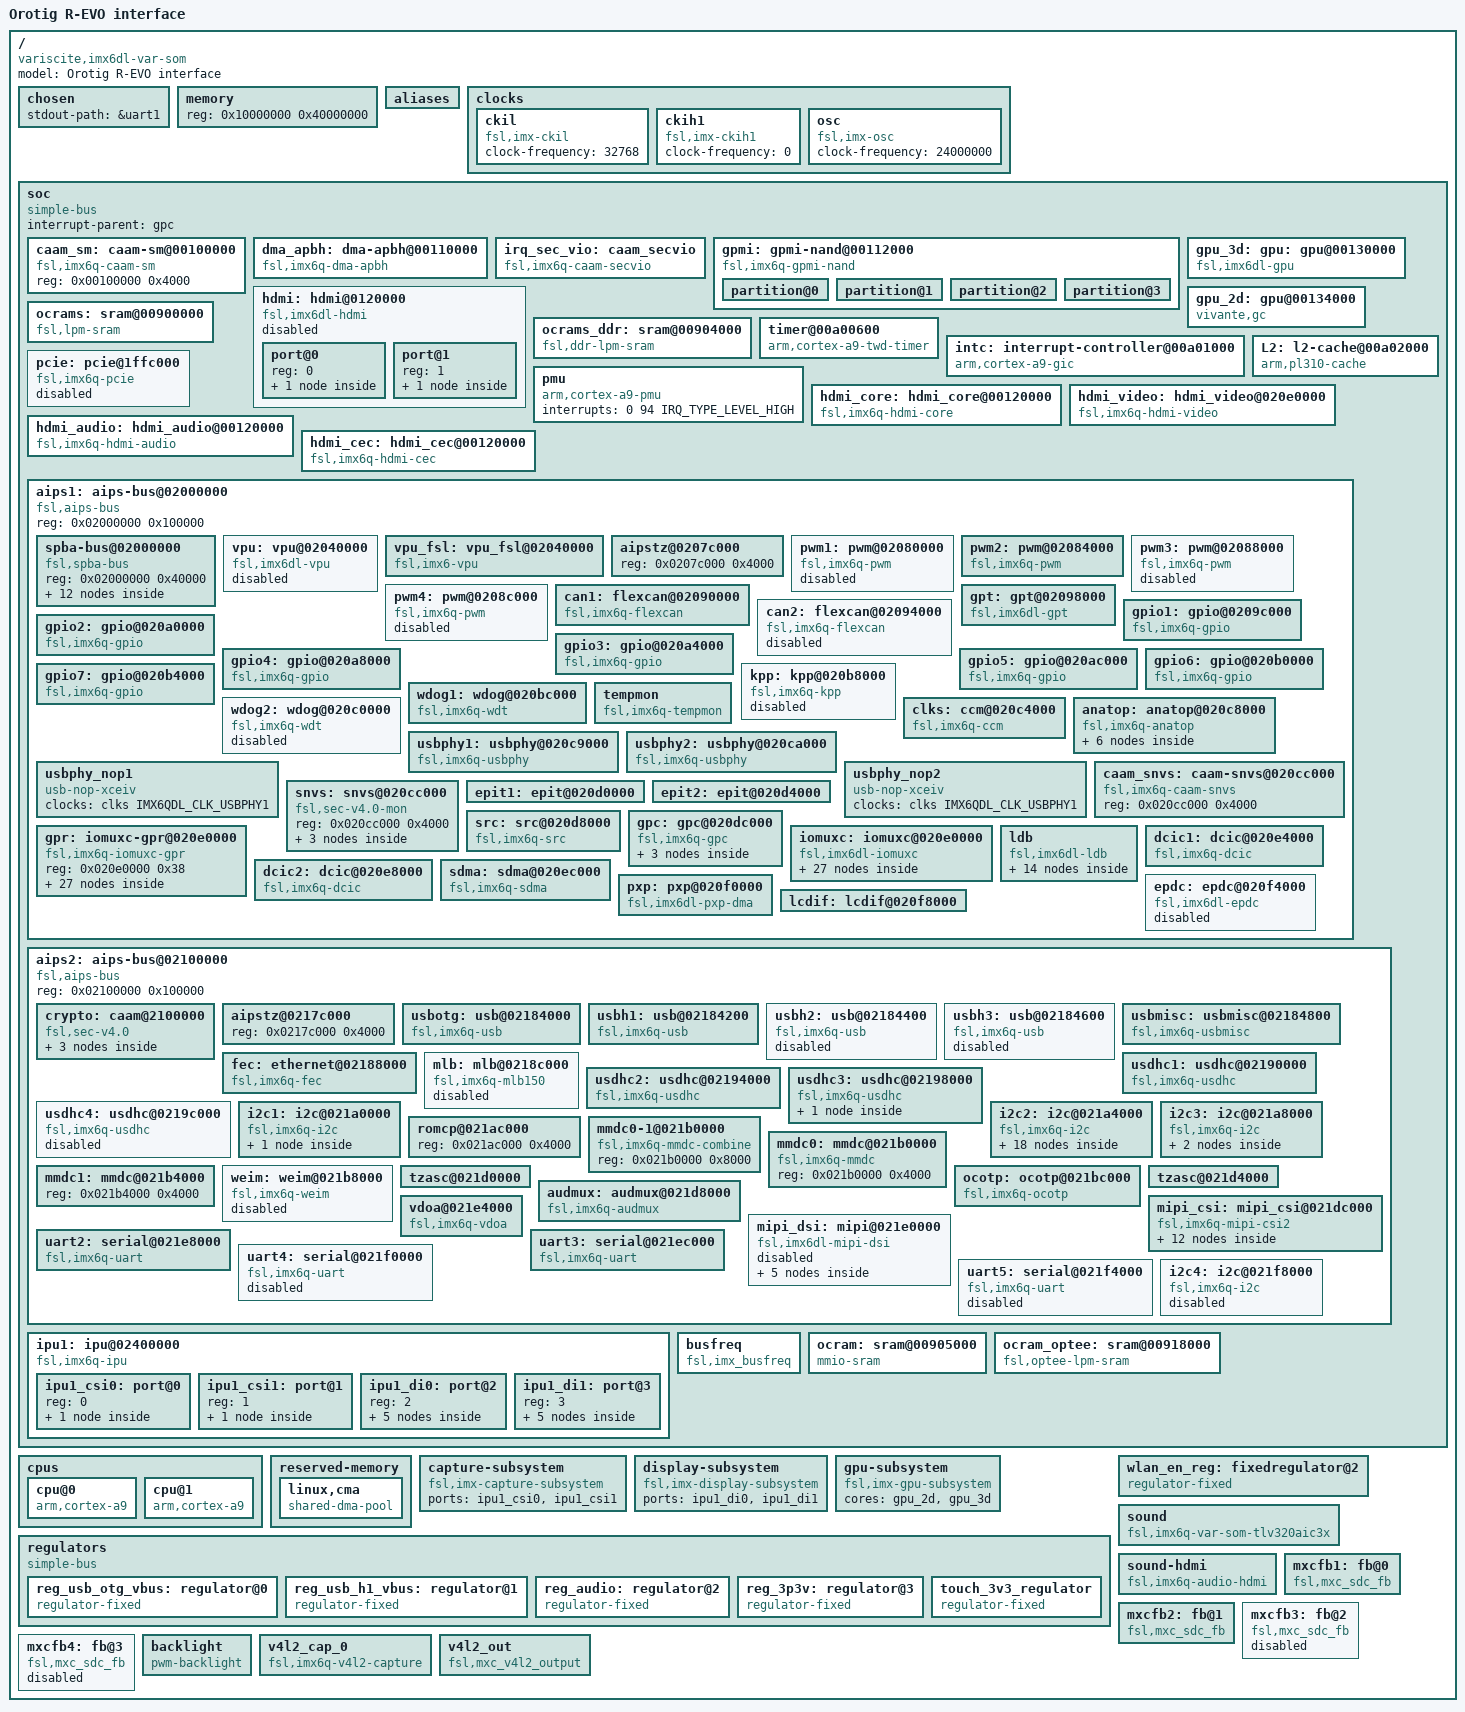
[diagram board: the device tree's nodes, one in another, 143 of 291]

/*
 * Copyright (C) 2015-2017 Variscite Ltd.
 *
 * This program is free software; you can redistribute it and/or modify
 * it under the terms of the GNU General Public License version 2 as
 * published by the Free Software Foundation.
 */

/dts-v1/;

#include <dt-bindings/interrupt-controller/irq.h>
#include "imx6dl-pinfunc.h"
#include <dt-bindings/clock/imx6qdl-clock.h>
#include <dt-bindings/input/input.h>
#include <dt-bindings/interrupt-controller/arm-gic.h>
#include <dt-bindings/gpio/gpio.h>

/ {
	model = "Orotig R-EVO interface";
	compatible = "variscite,imx6dl-var-som", "fsl,imx6dl";
};

/ {
	#address-cells = <1>;
	#size-cells = <1>;
	/*
	 * The decompressor and also some bootloaders rely on a
	 * pre-existing /chosen node to be available to insert the
	 * command line and merge other ATAGS info.
	 * Also for U-Boot there must be a pre-existing /memory node.
	 */
	chosen {};
	memory { device_type = "memory"; reg = <0 0>; };

	aliases {
		ethernet0 = &fec;
		can0 = &can1;
		can1 = &can2;
		gpio0 = &gpio1;
		gpio1 = &gpio2;
		gpio2 = &gpio3;
		gpio3 = &gpio4;
		gpio4 = &gpio5;
		gpio5 = &gpio6;
		gpio6 = &gpio7;
		i2c0 = &i2c1;
		i2c1 = &i2c2;
		i2c2 = &i2c3;
		ipu0 = &ipu1;
		mmc0 = &usdhc1;
		mmc1 = &usdhc2;
		mmc2 = &usdhc3;
		mmc3 = &usdhc4;
		serial0 = &uart1;
		serial1 = &uart2;
		serial2 = &uart3;
		serial3 = &uart4;
		serial4 = &uart5;
		spi0 = &ecspi1;
		spi1 = &ecspi2;
		spi2 = &ecspi3;
		spi3 = &ecspi4;
		usbphy0 = &usbphy1;
		usbphy1 = &usbphy2;
	};

	clocks {
		#address-cells = <1>;
		#size-cells = <0>;

		ckil {
			compatible = "fsl,imx-ckil", "fixed-clock";
			#clock-cells = <0>;
			clock-frequency = <32768>;
		};

		ckih1 {
			compatible = "fsl,imx-ckih1", "fixed-clock";
			#clock-cells = <0>;
			clock-frequency = <0>;
		};

		osc {
			compatible = "fsl,imx-osc", "fixed-clock";
			#clock-cells = <0>;
			clock-frequency = <24000000>;
		};
	};

	soc {
		#address-cells = <1>;
		#size-cells = <1>;
		compatible = "simple-bus";
		interrupt-parent = <&gpc>;
		ranges;

		caam_sm: caam-sm@00100000 {
			compatible = "fsl,imx6q-caam-sm";
			reg = <0x00100000 0x4000>;
		};

		dma_apbh: dma-apbh@00110000 {
			compatible = "fsl,imx6q-dma-apbh", "fsl,imx28-dma-apbh";
			reg = <0x00110000 0x2000>;
			interrupts = <0 13 IRQ_TYPE_LEVEL_HIGH>,
				     <0 13 IRQ_TYPE_LEVEL_HIGH>,
				     <0 13 IRQ_TYPE_LEVEL_HIGH>,
				     <0 13 IRQ_TYPE_LEVEL_HIGH>;
			interrupt-names = "gpmi0", "gpmi1", "gpmi2", "gpmi3";
			#dma-cells = <1>;
			dma-channels = <4>;
			clocks = <&clks IMX6QDL_CLK_APBH_DMA>;
		};

		irq_sec_vio: caam_secvio {
			compatible = "fsl,imx6q-caam-secvio";
			interrupts = <0 20 0x04>;
			secvio_src = <0x8000001d>;
			jtag-tamper = "disabled";
			watchdog-tamper = "enabled";
			internal-boot-tamper = "enabled";
			external-pin-tamper = "disabled";
		};

		gpmi: gpmi-nand@00112000 {
			compatible = "fsl,imx6q-gpmi-nand";
			#address-cells = <1>;
			#size-cells = <1>;
			reg = <0x00112000 0x2000>, <0x00114000 0x2000>;
			reg-names = "gpmi-nand", "bch";
			interrupts = <0 15 IRQ_TYPE_LEVEL_HIGH>;
			interrupt-names = "bch";
			clocks = <&clks IMX6QDL_CLK_GPMI_IO>,
				 <&clks IMX6QDL_CLK_GPMI_APB>,
				 <&clks IMX6QDL_CLK_GPMI_BCH>,
				 <&clks IMX6QDL_CLK_GPMI_BCH_APB>,
				 <&clks IMX6QDL_CLK_PER1_BCH>;
			clock-names = "gpmi_io", "gpmi_apb", "gpmi_bch",
				      "gpmi_bch_apb", "per1_bch";
			dmas = <&dma_apbh 0>;
			dma-names = "rx-tx";
			status = "disabled";
		};

		hdmi: hdmi@0120000 {
			#address-cells = <1>;
			#size-cells = <0>;
			reg = <0x00120000 0x9000>;
			interrupts = <0 115 0x04>;
			gpr = <&gpr>;
			clocks = <&clks IMX6QDL_CLK_HDMI_IAHB>,
				 <&clks IMX6QDL_CLK_HDMI_ISFR>;
			clock-names = "iahb", "isfr";
			status = "disabled";

			port@0 {
				reg = <0>;

				hdmi_mux_0: endpoint {
					remote-endpoint = <&ipu1_di0_hdmi>;
				};
			};

			port@1 {
				reg = <1>;

				hdmi_mux_1: endpoint {
					remote-endpoint = <&ipu1_di1_hdmi>;
				};
			};
		};

		gpu_3d: gpu@00130000 {
			compatible = "vivante,gc";
			reg = <0x00130000 0x4000>;
			interrupts = <0 9 IRQ_TYPE_LEVEL_HIGH>;
			clocks = <&clks IMX6QDL_CLK_GPU3D_AXI>,
				 <&clks IMX6QDL_CLK_GPU3D_CORE>,
				 <&clks IMX6QDL_CLK_GPU3D_SHADER>;
			clock-names = "bus", "core", "shader";
			power-domains = <&pd_pu>;
		};

		gpu_2d: gpu@00134000 {
			compatible = "vivante,gc";
			reg = <0x00134000 0x4000>;
			interrupts = <0 10 IRQ_TYPE_LEVEL_HIGH>;
			clocks = <&clks IMX6QDL_CLK_GPU2D_AXI>,
				 <&clks IMX6QDL_CLK_GPU2D_CORE>;
			clock-names = "bus", "core";
			power-domains = <&pd_pu>;
		};

		ocrams: sram@00900000 {
			compatible = "fsl,lpm-sram";
			reg = <0x00900000 0x4000>;
			clocks = <&clks IMX6QDL_CLK_OCRAM>;
		};

		ocrams_ddr: sram@00904000 {
			compatible = "fsl,ddr-lpm-sram";
			reg = <0x00904000 0x1000>;
			clocks = <&clks IMX6QDL_CLK_OCRAM>;
		};

		timer@00a00600 {
			compatible = "arm,cortex-a9-twd-timer";
			reg = <0x00a00600 0x20>;
			interrupts = <1 13 0xf01>;
			interrupt-parent = <&intc>;
			clocks = <&clks IMX6QDL_CLK_TWD>;
		};

		intc: interrupt-controller@00a01000 {
			compatible = "arm,cortex-a9-gic";
			#interrupt-cells = <3>;
			interrupt-controller;
			reg = <0x00a01000 0x1000>,
			      <0x00a00100 0x100>;
			interrupt-parent = <&intc>;
		};

		L2: l2-cache@00a02000 {
			compatible = "arm,pl310-cache";
			reg = <0x00a02000 0x1000>;
			interrupts = <0 92 IRQ_TYPE_LEVEL_HIGH>;
			cache-unified;
			cache-level = <2>;
			arm,tag-latency = <4 2 3>;
			arm,data-latency = <4 2 3>;
			arm,shared-override;
		};

		pcie: pcie@1ffc000 {
			compatible = "fsl,imx6q-pcie", "snps,dw-pcie";
			reg = <0x01ffc000 0x04000>,
			      <0x01f00000 0x80000>;
			reg-names = "dbi", "config";
			#address-cells = <3>;
			#size-cells = <2>;
			device_type = "pci";
			bus-range = <0x00 0xff>;
			ranges = <0x81000000 0 0          0x01f80000 0 0x00010000 /* downstream I/O */
				  0x82000000 0 0x01000000 0x01000000 0 0x00f00000>; /* non-prefetchable memory */
			num-lanes = <1>;
			interrupts = <GIC_SPI 120 IRQ_TYPE_LEVEL_HIGH>;
			interrupt-names = "msi";
			#interrupt-cells = <1>;
			interrupt-map-mask = <0 0 0 0x7>;
			interrupt-map = <0 0 0 1 &gpc GIC_SPI 123 IRQ_TYPE_LEVEL_HIGH>,
					<0 0 0 2 &gpc GIC_SPI 122 IRQ_TYPE_LEVEL_HIGH>,
					<0 0 0 3 &gpc GIC_SPI 121 IRQ_TYPE_LEVEL_HIGH>,
					<0 0 0 4 &gpc GIC_SPI 120 IRQ_TYPE_LEVEL_HIGH>;
			clocks = <&clks IMX6QDL_CLK_PCIE_AXI>,
				 <&clks IMX6QDL_CLK_LVDS1_GATE>,
				 <&clks IMX6QDL_CLK_PCIE_REF_125M>;
			clock-names = "pcie", "pcie_bus", "pcie_phy";
			fsl,max-link-speed = <2>;
			status = "disabled";
		};

		pmu {
			compatible = "arm,cortex-a9-pmu";
			interrupts = <0 94 IRQ_TYPE_LEVEL_HIGH>;
		};

		hdmi_core: hdmi_core@00120000 {
			compatible = "fsl,imx6q-hdmi-core";
			reg = <0x00120000 0x9000>;
			clocks = <&clks IMX6QDL_CLK_HDMI_ISFR>,
					<&clks IMX6QDL_CLK_HDMI_IAHB>,
					<&clks IMX6QDL_CLK_HSI_TX>;
			clock-names = "hdmi_isfr", "hdmi_iahb", "mipi_core";
			status = "disabled";
		};

		hdmi_video: hdmi_video@020e0000 {
			compatible = "fsl,imx6q-hdmi-video";
			reg = <0x020e0000 0x1000>;
			reg-names = "hdmi_gpr";
			interrupts = <0 115 IRQ_TYPE_LEVEL_HIGH>;
			clocks = <&clks IMX6QDL_CLK_HDMI_ISFR>,
					<&clks IMX6QDL_CLK_HDMI_IAHB>,
					<&clks IMX6QDL_CLK_HSI_TX>;
			clock-names = "hdmi_isfr", "hdmi_iahb", "mipi_core";
			status = "disabled";
		};

		hdmi_audio: hdmi_audio@00120000 {
			compatible = "fsl,imx6q-hdmi-audio";
			clocks = <&clks IMX6QDL_CLK_HDMI_ISFR>,
					<&clks IMX6QDL_CLK_HDMI_IAHB>,
					<&clks IMX6QDL_CLK_HSI_TX>;
			clock-names = "hdmi_isfr", "hdmi_iahb", "mipi_core";
			dmas = <&sdma 2 25 0>;
			dma-names = "tx";
			status = "disabled";
		};

		hdmi_cec: hdmi_cec@00120000 {
			compatible = "fsl,imx6q-hdmi-cec";
			interrupts = <0 115 IRQ_TYPE_LEVEL_HIGH>;
			status = "disabled";
		};

		aips-bus@02000000 { /* AIPS1 */
			compatible = "fsl,aips-bus", "simple-bus";
			#address-cells = <1>;
			#size-cells = <1>;
			reg = <0x02000000 0x100000>;
			ranges;

			spba-bus@02000000 {
				compatible = "fsl,spba-bus", "simple-bus";
				#address-cells = <1>;
				#size-cells = <1>;
				reg = <0x02000000 0x40000>;
				ranges;

				spdif: spdif@02004000 {
					compatible = "fsl,imx35-spdif";
					reg = <0x02004000 0x4000>;
					interrupts = <0 52 IRQ_TYPE_LEVEL_HIGH>;
					dmas = <&sdma 14 18 0>,
					       <&sdma 15 18 0>;
					dma-names = "rx", "tx";
					clocks = <&clks IMX6QDL_CLK_SPDIF_GCLK>, <&clks IMX6QDL_CLK_OSC>,
						 <&clks IMX6QDL_CLK_SPDIF>, <&clks IMX6QDL_CLK_ASRC>,
						 <&clks IMX6QDL_CLK_DUMMY>, <&clks IMX6QDL_CLK_ESAI_EXTAL>,
						 <&clks IMX6QDL_CLK_IPG>, <&clks IMX6QDL_CLK_MLB>,
						 <&clks IMX6QDL_CLK_DUMMY>, <&clks IMX6QDL_CLK_SPBA>;
					clock-names = "core",  "rxtx0",
						      "rxtx1", "rxtx2",
						      "rxtx3", "rxtx4",
						      "rxtx5", "rxtx6",
						      "rxtx7", "spba";
					status = "disabled";
				};

				ecspi1: ecspi@02008000 {
					#address-cells = <1>;
					#size-cells = <0>;
					compatible = "fsl,imx6q-ecspi", "fsl,imx51-ecspi";
					reg = <0x02008000 0x4000>;
					interrupts = <0 31 IRQ_TYPE_LEVEL_HIGH>;
					clocks = <&clks IMX6QDL_CLK_ECSPI1>,
						 <&clks IMX6QDL_CLK_ECSPI1>;
					clock-names = "ipg", "per";
					dmas = <&sdma 3 7 1>, <&sdma 4 7 2>;
					dma-names = "rx", "tx";
					status = "disabled";
				};

				ecspi2: ecspi@0200c000 {
					#address-cells = <1>;
					#size-cells = <0>;
					compatible = "fsl,imx6q-ecspi", "fsl,imx51-ecspi";
					reg = <0x0200c000 0x4000>;
					interrupts = <0 32 IRQ_TYPE_LEVEL_HIGH>;
					clocks = <&clks IMX6QDL_CLK_ECSPI2>,
						 <&clks IMX6QDL_CLK_ECSPI2>;
					clock-names = "ipg", "per";
					dmas = <&sdma 5 7 1>, <&sdma 6 7 2>;
					dma-names = "rx", "tx";
					status = "disabled";
				};

				ecspi3: ecspi@02010000 {
					#address-cells = <1>;
					#size-cells = <0>;
					compatible = "fsl,imx6q-ecspi", "fsl,imx51-ecspi";
					reg = <0x02010000 0x4000>;
					interrupts = <0 33 IRQ_TYPE_LEVEL_HIGH>;
					clocks = <&clks IMX6QDL_CLK_ECSPI3>,
						 <&clks IMX6QDL_CLK_ECSPI3>;
					clock-names = "ipg", "per";
					dmas = <&sdma 7 7 1>, <&sdma 8 7 2>;
					dma-names = "rx", "tx";
					status = "disabled";
				};

				ecspi4: ecspi@02014000 {
					#address-cells = <1>;
					#size-cells = <0>;
					compatible = "fsl,imx6q-ecspi", "fsl,imx51-ecspi";
					reg = <0x02014000 0x4000>;
					interrupts = <0 34 IRQ_TYPE_LEVEL_HIGH>;
					clocks = <&clks IMX6QDL_CLK_ECSPI4>,
						 <&clks IMX6QDL_CLK_ECSPI4>;
					clock-names = "ipg", "per";
					dmas = <&sdma 9 7 1>, <&sdma 10 7 2>;
					dma-names = "rx", "tx";
					status = "disabled";
				};

				uart1: serial@02020000 {
					compatible = "fsl,imx6q-uart", "fsl,imx21-uart";
					reg = <0x02020000 0x4000>;
					interrupts = <0 26 IRQ_TYPE_LEVEL_HIGH>;
					clocks = <&clks IMX6QDL_CLK_UART_IPG>,
						 <&clks IMX6QDL_CLK_UART_SERIAL>;
					clock-names = "ipg", "per";
					dmas = <&sdma 25 4 0>, <&sdma 26 4 0>;
					dma-names = "rx", "tx";
					status = "disabled";
				};

				esai: esai@02024000 {
					#sound-dai-cells = <0>;
					compatible = "fsl,imx35-esai";
					reg = <0x02024000 0x4000>;
					interrupts = <0 51 IRQ_TYPE_LEVEL_HIGH>;
					clocks = <&clks IMX6QDL_CLK_ESAI_IPG>,
						 <&clks IMX6QDL_CLK_ESAI_MEM>,
						 <&clks IMX6QDL_CLK_ESAI_EXTAL>,
						 <&clks IMX6QDL_CLK_ESAI_IPG>,
						 <&clks IMX6QDL_CLK_SPBA>;
					clock-names = "core", "mem", "extal", "fsys", "spba";
					dmas = <&sdma 23 21 0>, <&sdma 24 21 0>;
					dma-names = "rx", "tx";
					status = "disabled";
				};

				ssi1: ssi@02028000 {
					#sound-dai-cells = <0>;
					compatible = "fsl,imx6q-ssi",
							"fsl,imx51-ssi";
					reg = <0x02028000 0x4000>;
					interrupts = <0 46 IRQ_TYPE_LEVEL_HIGH>;
					clocks = <&clks IMX6QDL_CLK_SSI1_IPG>,
						 <&clks IMX6QDL_CLK_SSI1>;
					clock-names = "ipg", "baud";
					dmas = <&sdma 37 22 0>,
					       <&sdma 38 22 0>;
					dma-names = "rx", "tx";
					fsl,fifo-depth = <15>;
					status = "disabled";
				};

				ssi2: ssi@0202c000 {
					#sound-dai-cells = <0>;
					compatible = "fsl,imx6q-ssi",
							"fsl,imx51-ssi";
					reg = <0x0202c000 0x4000>;
					interrupts = <0 47 IRQ_TYPE_LEVEL_HIGH>;
					clocks = <&clks IMX6QDL_CLK_SSI2_IPG>,
						 <&clks IMX6QDL_CLK_SSI2>;
					clock-names = "ipg", "baud";
					dmas = <&sdma 41 22 0>,
					       <&sdma 42 22 0>;
					dma-names = "rx", "tx";
					fsl,fifo-depth = <15>;
					status = "disabled";
				};

				ssi3: ssi@02030000 {
					#sound-dai-cells = <0>;
					compatible = "fsl,imx6q-ssi",
							"fsl,imx51-ssi";
					reg = <0x02030000 0x4000>;
					interrupts = <0 48 IRQ_TYPE_LEVEL_HIGH>;
					clocks = <&clks IMX6QDL_CLK_SSI3_IPG>,
						 <&clks IMX6QDL_CLK_SSI3>;
					clock-names = "ipg", "baud";
					dmas = <&sdma 45 22 0>,
					       <&sdma 46 22 0>;
					dma-names = "rx", "tx";
					fsl,fifo-depth = <15>;
					status = "disabled";
				};

				asrc: asrc@02034000 {
					compatible = "fsl,imx53-asrc";
					reg = <0x02034000 0x4000>;
					interrupts = <0 50 IRQ_TYPE_LEVEL_HIGH>;
					clocks = <&clks IMX6QDL_CLK_ASRC_IPG>,
						<&clks IMX6QDL_CLK_ASRC_MEM>, <&clks 0>,
						<&clks 0>, <&clks 0>, <&clks 0>, <&clks 0>,
						<&clks 0>, <&clks 0>, <&clks 0>, <&clks 0>,
						<&clks 0>, <&clks 0>, <&clks 0>, <&clks 0>,
						<&clks IMX6QDL_CLK_ASRC>, <&clks 0>, <&clks 0>,
						<&clks IMX6QDL_CLK_SPBA>;
					clock-names = "mem", "ipg", "asrck_0",
						"asrck_1", "asrck_2", "asrck_3", "asrck_4",
						"asrck_5", "asrck_6", "asrck_7", "asrck_8",
						"asrck_9", "asrck_a", "asrck_b", "asrck_c",
						"asrck_d", "asrck_e", "asrck_f", "spba";
					dmas = <&sdma 17 23 1>, <&sdma 18 23 1>, <&sdma 19 23 1>,
						<&sdma 20 23 1>, <&sdma 21 23 1>, <&sdma 22 23 1>;
					dma-names = "rxa", "rxb", "rxc",
							"txa", "txb", "txc";
					fsl,asrc-rate  = <48000>;
					fsl,asrc-width = <16>;
					status = "okay";
				};

				spba@0203c000 {
					reg = <0x0203c000 0x4000>;
				};
			};

			vpu: vpu@02040000 {
				compatible = "cnm,coda960";
				reg = <0x02040000 0x3c000>;
				interrupts = <0 12 IRQ_TYPE_LEVEL_HIGH>,
					     <0 3 IRQ_TYPE_LEVEL_HIGH>;
				interrupt-names = "bit", "jpeg";
				clocks = <&clks IMX6QDL_CLK_VPU_AXI>,
					 <&clks IMX6QDL_CLK_MMDC_CH0_AXI>;
				clock-names = "per", "ahb";
				power-domains = <&pd_pu>;
				resets = <&src 1>;
				iram = <&ocram>;
				status = "disabled";
			};

			vpu_fsl: vpu_fsl@02040000 {
				compatible = "fsl,imx6-vpu";
				reg = <0x02040000 0x3c000>;
				reg-names = "vpu_regs";
				interrupts = <0 3 IRQ_TYPE_EDGE_RISING>,
				             <0 12 IRQ_TYPE_LEVEL_HIGH>;
				interrupt-names = "vpu_jpu_irq", "vpu_ipi_irq";
				clocks = <&clks IMX6QDL_CLK_VPU_AXI>,
					 <&clks IMX6QDL_CLK_MMDC_CH0_AXI>,
					 <&clks IMX6QDL_CLK_OCRAM>;
				clock-names = "vpu_clk", "mmdc_ch0_axi", "ocram";
				iramsize = <0x21000>;
				iram = <&ocram>;
				resets = <&src 1>;
				power-domains = <&pd_pu>;
			};

			aipstz@0207c000 { /* AIPSTZ1 */
				reg = <0x0207c000 0x4000>;
			};

			pwm1: pwm@02080000 {
				#pwm-cells = <2>;
				compatible = "fsl,imx6q-pwm", "fsl,imx27-pwm";
				reg = <0x02080000 0x4000>;
				interrupts = <0 83 IRQ_TYPE_LEVEL_HIGH>;
				clocks = <&clks IMX6QDL_CLK_IPG>,
					 <&clks IMX6QDL_CLK_PWM1>;
				clock-names = "ipg", "per";
				status = "disabled";
			};

			pwm2: pwm@02084000 {
				#pwm-cells = <2>;
				compatible = "fsl,imx6q-pwm", "fsl,imx27-pwm";
				reg = <0x02084000 0x4000>;
				interrupts = <0 84 IRQ_TYPE_LEVEL_HIGH>;
				clocks = <&clks IMX6QDL_CLK_IPG>,
					 <&clks IMX6QDL_CLK_PWM2>;
				clock-names = "ipg", "per";
				status = "disabled";
			};

			pwm3: pwm@02088000 {
				#pwm-cells = <2>;
				compatible = "fsl,imx6q-pwm", "fsl,imx27-pwm";
				reg = <0x02088000 0x4000>;
				interrupts = <0 85 IRQ_TYPE_LEVEL_HIGH>;
				clocks = <&clks IMX6QDL_CLK_IPG>,
					 <&clks IMX6QDL_CLK_PWM3>;
				clock-names = "ipg", "per";
				status = "disabled";
			};

			pwm4: pwm@0208c000 {
				#pwm-cells = <2>;
				compatible = "fsl,imx6q-pwm", "fsl,imx27-pwm";
				reg = <0x0208c000 0x4000>;
				interrupts = <0 86 IRQ_TYPE_LEVEL_HIGH>;
				clocks = <&clks IMX6QDL_CLK_IPG>,
					 <&clks IMX6QDL_CLK_PWM4>;
				clock-names = "ipg", "per";
				status = "disabled";
			};

			can1: flexcan@02090000 {
				compatible = "fsl,imx6q-flexcan";
				reg = <0x02090000 0x4000>;
				interrupts = <0 110 IRQ_TYPE_LEVEL_HIGH>;
				clocks = <&clks IMX6QDL_CLK_CAN1_IPG>,
					 <&clks IMX6QDL_CLK_CAN1_SERIAL>;
				clock-names = "ipg", "per";
				stop-mode = <&gpr 0x34 28 0x10 17>;
				status = "disabled";
			};

			can2: flexcan@02094000 {
				compatible = "fsl,imx6q-flexcan";
				reg = <0x02094000 0x4000>;
				interrupts = <0 111 IRQ_TYPE_LEVEL_HIGH>;
				clocks = <&clks IMX6QDL_CLK_CAN2_IPG>,
					 <&clks IMX6QDL_CLK_CAN2_SERIAL>;
				clock-names = "ipg", "per";
				stop-mode = <&gpr 0x34 29 0x10 18>;
				status = "disabled";
			};

			gpt: gpt@02098000 {
				compatible = "fsl,imx6q-gpt", "fsl,imx31-gpt";
				reg = <0x02098000 0x4000>;
				interrupts = <0 55 IRQ_TYPE_LEVEL_HIGH>;
				clocks = <&clks IMX6QDL_CLK_GPT_IPG>,
					 <&clks IMX6QDL_CLK_GPT_IPG_PER>,
					 <&clks IMX6QDL_CLK_GPT_3M>;
				clock-names = "ipg", "per", "osc_per";
			};

			gpio1: gpio@0209c000 {
				compatible = "fsl,imx6q-gpio", "fsl,imx35-gpio";
				reg = <0x0209c000 0x4000>;
				interrupts = <0 66 IRQ_TYPE_LEVEL_HIGH>,
					     <0 67 IRQ_TYPE_LEVEL_HIGH>;
				gpio-controller;
				#gpio-cells = <2>;
				interrupt-controller;
				#interrupt-cells = <2>;
			};

			gpio2: gpio@020a0000 {
				compatible = "fsl,imx6q-gpio", "fsl,imx35-gpio";
				reg = <0x020a0000 0x4000>;
				interrupts = <0 68 IRQ_TYPE_LEVEL_HIGH>,
					     <0 69 IRQ_TYPE_LEVEL_HIGH>;
				gpio-controller;
				#gpio-cells = <2>;
				interrupt-controller;
				#interrupt-cells = <2>;
			};

			gpio3: gpio@020a4000 {
				compatible = "fsl,imx6q-gpio", "fsl,imx35-gpio";
				reg = <0x020a4000 0x4000>;
				interrupts = <0 70 IRQ_TYPE_LEVEL_HIGH>,
					     <0 71 IRQ_TYPE_LEVEL_HIGH>;
				gpio-controller;
				#gpio-cells = <2>;
				interrupt-controller;
				#interrupt-cells = <2>;
			};

			gpio4: gpio@020a8000 {
				compatible = "fsl,imx6q-gpio", "fsl,imx35-gpio";
				reg = <0x020a8000 0x4000>;
				interrupts = <0 72 IRQ_TYPE_LEVEL_HIGH>,
					     <0 73 IRQ_TYPE_LEVEL_HIGH>;
				gpio-controller;
				#gpio-cells = <2>;
				interrupt-controller;
				#interrupt-cells = <2>;
			};

			gpio5: gpio@020ac000 {
				compatible = "fsl,imx6q-gpio", "fsl,imx35-gpio";
				reg = <0x020ac000 0x4000>;
				interrupts = <0 74 IRQ_TYPE_LEVEL_HIGH>,
					     <0 75 IRQ_TYPE_LEVEL_HIGH>;
				gpio-controller;
				#gpio-cells = <2>;
				interrupt-controller;
				#interrupt-cells = <2>;
			};

			gpio6: gpio@020b0000 {
				compatible = "fsl,imx6q-gpio", "fsl,imx35-gpio";
				reg = <0x020b0000 0x4000>;
				interrupts = <0 76 IRQ_TYPE_LEVEL_HIGH>,
					     <0 77 IRQ_TYPE_LEVEL_HIGH>;
				gpio-controller;
				#gpio-cells = <2>;
				interrupt-controller;
				#interrupt-cells = <2>;
			};

			gpio7: gpio@020b4000 {
				compatible = "fsl,imx6q-gpio", "fsl,imx35-gpio";
				reg = <0x020b4000 0x4000>;
				interrupts = <0 78 IRQ_TYPE_LEVEL_HIGH>,
					     <0 79 IRQ_TYPE_LEVEL_HIGH>;
				gpio-controller;
				#gpio-cells = <2>;
				interrupt-controller;
				#interrupt-cells = <2>;
			};

			kpp: kpp@020b8000 {
				compatible = "fsl,imx6q-kpp", "fsl,imx21-kpp";
				reg = <0x020b8000 0x4000>;
				interrupts = <0 82 IRQ_TYPE_LEVEL_HIGH>;
				clocks = <&clks IMX6QDL_CLK_IPG>;
				status = "disabled";
			};

			wdog1: wdog@020bc000 {
				compatible = "fsl,imx6q-wdt", "fsl,imx21-wdt";
				reg = <0x020bc000 0x4000>;
				interrupts = <0 80 IRQ_TYPE_LEVEL_HIGH>;
				clocks = <&clks IMX6QDL_CLK_DUMMY>;
			};

			wdog2: wdog@020c0000 {
				compatible = "fsl,imx6q-wdt", "fsl,imx21-wdt";
				reg = <0x020c0000 0x4000>;
				interrupts = <0 81 IRQ_TYPE_LEVEL_HIGH>;
				clocks = <&clks IMX6QDL_CLK_DUMMY>;
				status = "disabled";
			};

			clks: ccm@020c4000 {
				compatible = "fsl,imx6q-ccm";
				reg = <0x020c4000 0x4000>;
				interrupts = <0 87 IRQ_TYPE_LEVEL_HIGH>,
					     <0 88 IRQ_TYPE_LEVEL_HIGH>;
				#clock-cells = <1>;
			};

			anatop: anatop@020c8000 {
				compatible = "fsl,imx6q-anatop", "syscon", "simple-bus";
				reg = <0x020c8000 0x1000>;
				interrupts = <0 49 IRQ_TYPE_LEVEL_HIGH>,
					     <0 54 IRQ_TYPE_LEVEL_HIGH>,
					     <0 127 IRQ_TYPE_LEVEL_HIGH>;

				regulator-1p1 {
					compatible = "fsl,anatop-regulator";
					regulator-name = "vdd1p1";
					regulator-min-microvolt = <1000000>;
					regulator-max-microvolt = <1200000>;
					regulator-always-on;
					anatop-reg-offset = <0x110>;
					anatop-vol-bit-shift = <8>;
					anatop-vol-bit-width = <5>;
					anatop-min-bit-val = <4>;
					anatop-min-voltage = <800000>;
					anatop-max-voltage = <1375000>;
					anatop-enable-bit = <0>;
				};

				anatop_reg_3p0: regulator-3p0@120 {
					compatible = "fsl,anatop-regulator";
					regulator-name = "vdd3p0";
					regulator-min-microvolt = <2625000>;
					regulator-max-microvolt = <3400000>;
					anatop-reg-offset = <0x120>;
					anatop-vol-bit-shift = <8>;
					anatop-vol-bit-width = <5>;
					anatop-min-bit-val = <0>;
					anatop-min-voltage = <2625000>;
					anatop-max-voltage = <3400000>;
					anatop-enable-bit = <0>;
				};

				regulator-2p5 {
					compatible = "fsl,anatop-regulator";
					regulator-name = "vdd2p5";
					regulator-min-microvolt = <2250000>;
					regulator-max-microvolt = <2750000>;
					regulator-always-on;
					anatop-reg-offset = <0x130>;
					anatop-vol-bit-shift = <8>;
					anatop-vol-bit-width = <5>;
					anatop-min-bit-val = <0>;
					anatop-min-voltage = <2100000>;
					anatop-max-voltage = <2875000>;
					anatop-enable-bit = <0>;
				};

				reg_arm: regulator-vddcore {
					compatible = "fsl,anatop-regulator";
					regulator-name = "vddarm";
					regulator-min-microvolt = <725000>;
					regulator-max-microvolt = <1450000>;
					regulator-always-on;
					anatop-reg-offset = <0x140>;
					anatop-vol-bit-shift = <0>;
					anatop-vol-bit-width = <5>;
					anatop-delay-reg-offset = <0x170>;
					anatop-delay-bit-shift = <24>;
					anatop-delay-bit-width = <2>;
					anatop-min-bit-val = <1>;
					anatop-min-voltage = <725000>;
					anatop-max-voltage = <1450000>;
					regulator-allow-bypass;
				};

				reg_pu: regulator-vddpu {
					compatible = "fsl,anatop-regulator";
					regulator-name = "vddpu";
					regulator-min-microvolt = <725000>;
					regulator-max-microvolt = <1450000>;
					regulator-enable-ramp-delay = <150>;
					anatop-reg-offset = <0x140>;
					anatop-vol-bit-shift = <9>;
					anatop-vol-bit-width = <5>;
					anatop-delay-reg-offset = <0x170>;
					anatop-delay-bit-shift = <26>;
					anatop-delay-bit-width = <2>;
					anatop-min-bit-val = <1>;
					anatop-min-voltage = <725000>;
					anatop-max-voltage = <1450000>;
					regulator-allow-bypass;
				};

				reg_soc: regulator-vddsoc {
					compatible = "fsl,anatop-regulator";
					regulator-name = "vddsoc";
					regulator-min-microvolt = <725000>;
					regulator-max-microvolt = <1450000>;
					regulator-always-on;
					anatop-reg-offset = <0x140>;
					anatop-vol-bit-shift = <18>;
					anatop-vol-bit-width = <5>;
					anatop-delay-reg-offset = <0x170>;
					anatop-delay-bit-shift = <28>;
					anatop-delay-bit-width = <2>;
					anatop-min-bit-val = <1>;
					anatop-min-voltage = <725000>;
					anatop-max-voltage = <1450000>;
					regulator-allow-bypass;
				};
			};

			tempmon: tempmon {
				compatible = "fsl,imx6q-tempmon";
				interrupts = <0 49 IRQ_TYPE_LEVEL_HIGH>;
				fsl,tempmon = <&anatop>;
				fsl,tempmon-data = <&ocotp>;
				clocks = <&clks IMX6QDL_CLK_PLL3_USB_OTG>;
			};

			usbphy1: usbphy@020c9000 {
				compatible = "fsl,imx6q-usbphy", "fsl,imx23-usbphy";
				reg = <0x020c9000 0x1000>;
				interrupts = <0 44 IRQ_TYPE_LEVEL_HIGH>;
				clocks = <&clks IMX6QDL_CLK_USBPHY1>;
				phy-3p0-supply = <&anatop_reg_3p0>;
				fsl,anatop = <&anatop>;
			};

			usbphy2: usbphy@020ca000 {
				compatible = "fsl,imx6q-usbphy", "fsl,imx23-usbphy";
				reg = <0x020ca000 0x1000>;
				interrupts = <0 45 IRQ_TYPE_LEVEL_HIGH>;
				clocks = <&clks IMX6QDL_CLK_USBPHY2>;
				phy-3p0-supply = <&anatop_reg_3p0>;
				fsl,anatop = <&anatop>;
			};

			usbphy_nop1: usbphy_nop1 {
				compatible = "usb-nop-xceiv";
				clocks = <&clks IMX6QDL_CLK_USBPHY1>;
				clock-names = "main_clk";
			};

			usbphy_nop2: usbphy_nop2 {
				compatible = "usb-nop-xceiv";
				clocks = <&clks IMX6QDL_CLK_USBPHY1>;
				clock-names = "main_clk";
			};

			caam_snvs: caam-snvs@020cc000 {
				compatible = "fsl,imx6q-caam-snvs";
				reg = <0x020cc000 0x4000>;
			};

			snvs: snvs@020cc000 {
				compatible = "fsl,sec-v4.0-mon", "syscon", "simple-mfd";
				reg = <0x020cc000 0x4000>;

				snvs_rtc: snvs-rtc-lp {
					compatible = "fsl,sec-v4.0-mon-rtc-lp";
					regmap = <&snvs>;
					offset = <0x34>;
					interrupts = <0 19 IRQ_TYPE_LEVEL_HIGH>,
						     <0 20 IRQ_TYPE_LEVEL_HIGH>;
				};

				snvs_poweroff: snvs-poweroff {
					compatible = "syscon-poweroff";
					regmap = <&snvs>;
					offset = <0x38>;
					value = <0x61>;
					mask = <0x61>;
					status = "disabled";
				};

				snvs_pwrkey: snvs-powerkey {
					compatible = "fsl,sec-v4.0-pwrkey";
					regmap = <&snvs>;
					interrupts = <GIC_SPI 4 IRQ_TYPE_LEVEL_HIGH>;
					linux,keycode = <KEY_POWER>;
					key-release-only;
					wakeup-source;
					status = "disabled";
				};
			};

			epit1: epit@020d0000 { /* EPIT1 */
				reg = <0x020d0000 0x4000>;
				interrupts = <0 56 IRQ_TYPE_LEVEL_HIGH>;
			};

			epit2: epit@020d4000 { /* EPIT2 */
				reg = <0x020d4000 0x4000>;
				interrupts = <0 57 IRQ_TYPE_LEVEL_HIGH>;
			};

			src: src@020d8000 {
				compatible = "fsl,imx6q-src", "fsl,imx51-src";
				reg = <0x020d8000 0x4000>;
				interrupts = <0 91 IRQ_TYPE_LEVEL_HIGH>,
					     <0 96 IRQ_TYPE_LEVEL_HIGH>;
				#reset-cells = <1>;
			};

			gpc: gpc@020dc000 {
				compatible = "fsl,imx6q-gpc";
				reg = <0x020dc000 0x4000>;
				interrupt-controller;
				#interrupt-cells = <3>;
				interrupts = <0 89 IRQ_TYPE_LEVEL_HIGH>,
					     <0 90 IRQ_TYPE_LEVEL_HIGH>;
				interrupt-parent = <&intc>;
				clocks = <&clks IMX6QDL_CLK_IPG>;
				clock-names = "ipg";

				pgc {
					#address-cells = <1>;
					#size-cells = <0>;

					power-domain@0 {
						reg = <0>;
						#power-domain-cells = <0>;
					};
					pd_pu: power-domain@1 {
						reg = <1>;
						#power-domain-cells = <0>;
						power-supply = <&reg_pu>;
						clocks = <&clks IMX6QDL_CLK_GPU3D_CORE>,
						         <&clks IMX6QDL_CLK_GPU3D_SHADER>,
						         <&clks IMX6QDL_CLK_GPU2D_CORE>,
						         <&clks IMX6QDL_CLK_GPU2D_AXI>,
						         <&clks IMX6QDL_CLK_OPENVG_AXI>,
						         <&clks IMX6QDL_CLK_VPU_AXI>;
					};
				};
			};

			gpr: iomuxc-gpr@020e0000 {
				compatible = "fsl,imx6q-iomuxc-gpr", "syscon", "simple-mfd";
				reg = <0x020e0000 0x38>;

				mux: mux-controller {
					compatible = "mmio-mux";
					#mux-control-cells = <1>;
				};
			};

			iomuxc: iomuxc@020e0000 {
				compatible = "fsl,imx6dl-iomuxc", "fsl,imx6q-iomuxc";
				reg = <0x020e0000 0x4000>;
			};

			ldb: ldb {
				#address-cells = <1>;
				#size-cells = <0>;
				compatible = "fsl,imx6q-ldb", "fsl,imx53-ldb";
				gpr = <&gpr>;
				status = "disabled";

				lvds-channel@0 {
					#address-cells = <1>;
					#size-cells = <0>;
					reg = <0>;
					status = "disabled";

					port@0 {
						reg = <0>;

						lvds0_mux_0: endpoint {
							remote-endpoint = <&ipu1_di0_lvds0>;
						};
					};

					port@1 {
						reg = <1>;

						lvds0_mux_1: endpoint {
							remote-endpoint = <&ipu1_di1_lvds0>;
						};
					};
				};

				lvds-channel@1 {
					#address-cells = <1>;
					#size-cells = <0>;
					reg = <1>;
					status = "disabled";

					port@0 {
						reg = <0>;

						lvds1_mux_0: endpoint {
							remote-endpoint = <&ipu1_di0_lvds1>;
						};
					};

					port@1 {
						reg = <1>;

						lvds1_mux_1: endpoint {
							remote-endpoint = <&ipu1_di1_lvds1>;
						};
					};
				};
			};

			dcic1: dcic@020e4000 {
				compatible = "fsl,imx6q-dcic";
				reg = <0x020e4000 0x4000>;
				interrupts = <0 124 IRQ_TYPE_LEVEL_HIGH>;
				clocks = <&clks IMX6QDL_CLK_DCIC1>, <&clks IMX6QDL_CLK_DCIC1>;
				clock-names = "dcic", "disp-axi";
				gpr = <&gpr>;
				status = "disabled";
			};

			dcic2: dcic@020e8000 {
				compatible = "fsl,imx6q-dcic";
				reg = <0x020e8000 0x4000>;
				interrupts = <0 125 IRQ_TYPE_LEVEL_HIGH>;
				clocks = <&clks IMX6QDL_CLK_DCIC2>, <&clks IMX6QDL_CLK_DCIC2>;
				clock-names = "dcic", "disp-axi";
				gpr = <&gpr>;
				status = "disabled";
			};

			sdma: sdma@020ec000 {
				compatible = "fsl,imx6q-sdma", "fsl,imx35-sdma";
				reg = <0x020ec000 0x4000>;
				interrupts = <0 2 IRQ_TYPE_LEVEL_HIGH>;
				clocks = <&clks IMX6QDL_CLK_SDMA>,
					 <&clks IMX6QDL_CLK_SDMA>;
				clock-names = "ipg", "ahb";
				#dma-cells = <3>;
				fsl,sdma-ram-script-name = "imx/sdma/sdma-imx6q.bin";
			};
		};

		aips-bus@02100000 { /* AIPS2 */
			compatible = "fsl,aips-bus", "simple-bus";
			#address-cells = <1>;
			#size-cells = <1>;
			reg = <0x02100000 0x100000>;
			ranges;

			crypto: caam@2100000 {
				compatible = "fsl,sec-v4.0";
				#address-cells = <1>;
				#size-cells = <1>;
				reg = <0x2100000 0x10000>;
				ranges = <0 0x2100000 0x40000>;
				interrupt-parent = <&intc>; /* interrupts = <0 92 0x4>; */
				clocks = <&clks IMX6QDL_CLK_CAAM_MEM>,
					 <&clks IMX6QDL_CLK_CAAM_ACLK>,
					 <&clks IMX6QDL_CLK_CAAM_IPG>,
					 <&clks IMX6QDL_CLK_EIM_SLOW>;
				clock-names = "mem", "aclk", "ipg", "emi_slow";

				sec_ctrl: ctrl@0 {
					/* CAAM Page 0 only accessible */
					/*	by secure world */
					compatible = "fsl,sec-v4.0-ctrl";
					reg = <0x2100000 0x1000>;
					secure-status = "okay";
					status = "disabled";
				};

				sec_jr0: jr0@1000 {
					compatible = "fsl,sec-v4.0-job-ring";
					reg = <0x1000 0x1000>;
					interrupts = <GIC_SPI 105 IRQ_TYPE_LEVEL_HIGH>;
				};

				sec_jr1: jr1@2000 {
					compatible = "fsl,sec-v4.0-job-ring";
					reg = <0x2000 0x1000>;
					interrupts = <GIC_SPI 106 IRQ_TYPE_LEVEL_HIGH>;
				};
			};

			aipstz@0217c000 { /* AIPSTZ2 */
				reg = <0x0217c000 0x4000>;
			};

			usbotg: usb@02184000 {
				compatible = "fsl,imx6q-usb", "fsl,imx27-usb";
				reg = <0x02184000 0x200>;
				interrupts = <0 43 IRQ_TYPE_LEVEL_HIGH>;
				clocks = <&clks IMX6QDL_CLK_USBOH3>;
				fsl,usbphy = <&usbphy1>;
				fsl,usbmisc = <&usbmisc 0>;
				ahb-burst-config = <0x0>;
				tx-burst-size-dword = <0x10>;
				rx-burst-size-dword = <0x10>;
				fsl,anatop = <&anatop>;
				status = "disabled";
			};

			usbh1: usb@02184200 {
				compatible = "fsl,imx6q-usb", "fsl,imx27-usb";
				reg = <0x02184200 0x200>;
				interrupts = <0 40 IRQ_TYPE_LEVEL_HIGH>;
				clocks = <&clks IMX6QDL_CLK_USBOH3>;
				fsl,usbphy = <&usbphy2>;
				fsl,usbmisc = <&usbmisc 1>;
				dr_mode = "host";
				ahb-burst-config = <0x0>;
				tx-burst-size-dword = <0x10>;
				rx-burst-size-dword = <0x10>;
				status = "disabled";
			};

			usbh2: usb@02184400 {
				compatible = "fsl,imx6q-usb", "fsl,imx27-usb";
				reg = <0x02184400 0x200>;
				interrupts = <0 41 IRQ_TYPE_LEVEL_HIGH>;
				clocks = <&clks IMX6QDL_CLK_USBOH3>;
				fsl,usbmisc = <&usbmisc 2>;
				dr_mode = "host";
				ahb-burst-config = <0x0>;
				tx-burst-size-dword = <0x10>;
				rx-burst-size-dword = <0x10>;
				phy_type = "hsic";
				fsl,usbphy = <&usbphy_nop1>;
				fsl,anatop = <&anatop>;
				status = "disabled";
			};

			usbh3: usb@02184600 {
				compatible = "fsl,imx6q-usb", "fsl,imx27-usb";
				reg = <0x02184600 0x200>;
				interrupts = <0 42 IRQ_TYPE_LEVEL_HIGH>;
				clocks = <&clks IMX6QDL_CLK_USBOH3>;
				fsl,usbmisc = <&usbmisc 3>;
				dr_mode = "host";
				ahb-burst-config = <0x0>;
				tx-burst-size-dword = <0x10>;
				rx-burst-size-dword = <0x10>;
				phy_type = "hsic";
				fsl,usbphy = <&usbphy_nop2>;
				fsl,anatop = <&anatop>;
				status = "disabled";
			};

			usbmisc: usbmisc@02184800 {
				#index-cells = <1>;
				compatible = "fsl,imx6q-usbmisc";
				reg = <0x02184800 0x200>;
				clocks = <&clks IMX6QDL_CLK_USBOH3>;
			};

			fec: ethernet@02188000 {
				compatible = "fsl,imx6q-fec";
				reg = <0x02188000 0x4000>;
				interrupts-extended =
					<&gpc 0 118 IRQ_TYPE_LEVEL_HIGH>,
					<&gpc 0 119 IRQ_TYPE_LEVEL_HIGH>;
				clocks = <&clks IMX6QDL_CLK_ENET>,
					 <&clks IMX6QDL_CLK_ENET>,
					 <&clks IMX6QDL_CLK_ENET_REF>;
				clock-names = "ipg", "ahb", "ptp";
				stop-mode = <&gpr 0x34 27>;
				fsl,wakeup_irq = <0>;
				status = "disabled";
			};

			mlb: mlb@0218c000 {
				compatible = "fsl,imx6q-mlb150";
				reg = <0x0218c000 0x4000>;
				interrupts = <0 53 IRQ_TYPE_LEVEL_HIGH>,
					     <0 117 IRQ_TYPE_LEVEL_HIGH>,
					     <0 126 IRQ_TYPE_LEVEL_HIGH>;
				clocks = <&clks IMX6QDL_CLK_MLB>;
				clock-names = "mlb";
				iram = <&ocram>;
				status = "disabled";
			};

			usdhc1: usdhc@02190000 {
				compatible = "fsl,imx6q-usdhc";
				reg = <0x02190000 0x4000>;
				interrupts = <0 22 IRQ_TYPE_LEVEL_HIGH>;
				clocks = <&clks IMX6QDL_CLK_USDHC1>,
					 <&clks IMX6QDL_CLK_USDHC1>,
					 <&clks IMX6QDL_CLK_USDHC1>;
				clock-names = "ipg", "ahb", "per";
				bus-width = <4>;
				status = "disabled";
			};

			usdhc2: usdhc@02194000 {
				compatible = "fsl,imx6q-usdhc";
				reg = <0x02194000 0x4000>;
				interrupts = <0 23 IRQ_TYPE_LEVEL_HIGH>;
				clocks = <&clks IMX6QDL_CLK_USDHC2>,
					 <&clks IMX6QDL_CLK_USDHC2>,
					 <&clks IMX6QDL_CLK_USDHC2>;
				clock-names = "ipg", "ahb", "per";
				bus-width = <4>;
				status = "disabled";
			};

			usdhc3: usdhc@02198000 {
				compatible = "fsl,imx6q-usdhc";
				reg = <0x02198000 0x4000>;
				interrupts = <0 24 IRQ_TYPE_LEVEL_HIGH>;
				clocks = <&clks IMX6QDL_CLK_USDHC3>,
					 <&clks IMX6QDL_CLK_USDHC3>,
					 <&clks IMX6QDL_CLK_USDHC3>;
				clock-names = "ipg", "ahb", "per";
				bus-width = <4>;
				status = "disabled";
			};

			usdhc4: usdhc@0219c000 {
				compatible = "fsl,imx6q-usdhc";
				reg = <0x0219c000 0x4000>;
				interrupts = <0 25 IRQ_TYPE_LEVEL_HIGH>;
				clocks = <&clks IMX6QDL_CLK_USDHC4>,
					 <&clks IMX6QDL_CLK_USDHC4>,
					 <&clks IMX6QDL_CLK_USDHC4>;
				clock-names = "ipg", "ahb", "per";
				bus-width = <4>;
				status = "disabled";
			};

			i2c1: i2c@021a0000 {
				#address-cells = <1>;
				#size-cells = <0>;
				compatible = "fsl,imx6q-i2c", "fsl,imx21-i2c";
				reg = <0x021a0000 0x4000>;
				interrupts = <0 36 IRQ_TYPE_LEVEL_HIGH>;
				clocks = <&clks IMX6QDL_CLK_I2C1>;
				status = "disabled";
			};

			i2c2: i2c@021a4000 {
				#address-cells = <1>;
				#size-cells = <0>;
				compatible = "fsl,imx6q-i2c", "fsl,imx21-i2c";
				reg = <0x021a4000 0x4000>;
				interrupts = <0 37 IRQ_TYPE_LEVEL_HIGH>;
				clocks = <&clks IMX6QDL_CLK_I2C2>;
				status = "disabled";
			};

			i2c3: i2c@021a8000 {
				#address-cells = <1>;
				#size-cells = <0>;
				compatible = "fsl,imx6q-i2c", "fsl,imx21-i2c";
				reg = <0x021a8000 0x4000>;
				interrupts = <0 38 IRQ_TYPE_LEVEL_HIGH>;
				clocks = <&clks IMX6QDL_CLK_I2C3>;
				status = "disabled";
			};

			romcp@021ac000 {
				reg = <0x021ac000 0x4000>;
			};

			mmdc0-1@021b0000 { /* MMDC0-1 */
				compatible = "fsl,imx6q-mmdc-combine";
				reg = <0x021b0000 0x8000>;
			};

			mmdc0: mmdc@021b0000 { /* MMDC0 */
				compatible = "fsl,imx6q-mmdc";
				reg = <0x021b0000 0x4000>;
			};

			mmdc1: mmdc@021b4000 { /* MMDC1 */
				reg = <0x021b4000 0x4000>;
			};

			weim: weim@021b8000 {
				#address-cells = <2>;
				#size-cells = <1>;
				compatible = "fsl,imx6q-weim";
				reg = <0x021b8000 0x4000>;
				interrupts = <0 14 IRQ_TYPE_LEVEL_HIGH>;
				clocks = <&clks IMX6QDL_CLK_EIM_SLOW>;
				fsl,weim-cs-gpr = <&gpr>;
				status = "disabled";
			};

			ocotp: ocotp@021bc000 {
				compatible = "fsl,imx6q-ocotp", "syscon";
				reg = <0x021bc000 0x4000>;
				clocks = <&clks IMX6QDL_CLK_IIM>;
			};

			tzasc@021d0000 { /* TZASC1 */
				reg = <0x021d0000 0x4000>;
				interrupts = <0 108 IRQ_TYPE_LEVEL_HIGH>;
			};

			tzasc@021d4000 { /* TZASC2 */
				reg = <0x021d4000 0x4000>;
				interrupts = <0 109 IRQ_TYPE_LEVEL_HIGH>;
			};

			audmux: audmux@021d8000 {
				compatible = "fsl,imx6q-audmux", "fsl,imx31-audmux";
				reg = <0x021d8000 0x4000>;
				status = "disabled";
			};

			mipi_csi: mipi_csi@021dc000 { /* MIPI-CSI */
				compatible = "fsl,imx6q-mipi-csi2";
				reg = <0x021dc000 0x4000>;
				#address-cells = <1>;
				#size-cells = <0>;
				interrupts = <0 100 0x04>, <0 101 0x04>;
				clocks = <&clks IMX6QDL_CLK_HSI_TX>,
					 <&clks IMX6QDL_CLK_EIM_SEL>,
					 <&clks IMX6QDL_CLK_VIDEO_27M>;
				/* Note: clks 138 is hsi_tx, however, the dphy_c
				 * hsi_tx and pll_refclk use the same clk gate.
				 * In current clk driver, open/close clk gate do
				 * use hsi_tx for a temporary debug purpose.
				 */
				clock-names = "dphy_clk", "pixel_clk", "cfg_clk";
				status = "disabled";
			};

			mipi_dsi: mipi@021e0000 { /* MIPI-DSI */
				#address-cells = <1>;
				#size-cells = <0>;
				reg = <0x021e0000 0x4000>;
				status = "disabled";

				ports {
					#address-cells = <1>;
					#size-cells = <0>;

					port@0 {
						reg = <0>;

						mipi_mux_0: endpoint {
							remote-endpoint = <&ipu1_di0_mipi>;
						};
					};

					port@1 {
						reg = <1>;

						mipi_mux_1: endpoint {
							remote-endpoint = <&ipu1_di1_mipi>;
						};
					};
				};
			};

			vdoa@021e4000 {
				compatible = "fsl,imx6q-vdoa";
				reg = <0x021e4000 0x4000>;
				interrupts = <0 18 IRQ_TYPE_LEVEL_HIGH>;
				clocks = <&clks IMX6QDL_CLK_VDOA>;
				iram = <&ocram>;
			};

			uart2: serial@021e8000 {
				compatible = "fsl,imx6q-uart", "fsl,imx21-uart";
				reg = <0x021e8000 0x4000>;
				interrupts = <0 27 IRQ_TYPE_LEVEL_HIGH>;
				clocks = <&clks IMX6QDL_CLK_UART_IPG>,
					 <&clks IMX6QDL_CLK_UART_SERIAL>;
				clock-names = "ipg", "per";
				dmas = <&sdma 27 4 0>, <&sdma 28 4 0>;
				dma-names = "rx", "tx";
				status = "disabled";
			};

			uart3: serial@021ec000 {
				compatible = "fsl,imx6q-uart", "fsl,imx21-uart";
				reg = <0x021ec000 0x4000>;
				interrupts = <0 28 IRQ_TYPE_LEVEL_HIGH>;
				clocks = <&clks IMX6QDL_CLK_UART_IPG>,
					 <&clks IMX6QDL_CLK_UART_SERIAL>;
				clock-names = "ipg", "per";
				dmas = <&sdma 29 4 0>, <&sdma 30 4 0>;
				dma-names = "rx", "tx";
				status = "disabled";
			};

			uart4: serial@021f0000 {
				compatible = "fsl,imx6q-uart", "fsl,imx21-uart";
				reg = <0x021f0000 0x4000>;
				interrupts = <0 29 IRQ_TYPE_LEVEL_HIGH>;
				clocks = <&clks IMX6QDL_CLK_UART_IPG>,
					 <&clks IMX6QDL_CLK_UART_SERIAL>;
				clock-names = "ipg", "per";
				dmas = <&sdma 31 4 0>, <&sdma 32 4 0>;
				dma-names = "rx", "tx";
				status = "disabled";
			};

			uart5: serial@021f4000 {
				compatible = "fsl,imx6q-uart", "fsl,imx21-uart";
				reg = <0x021f4000 0x4000>;
				interrupts = <0 30 IRQ_TYPE_LEVEL_HIGH>;
				clocks = <&clks IMX6QDL_CLK_UART_IPG>,
					 <&clks IMX6QDL_CLK_UART_SERIAL>;
				clock-names = "ipg", "per";
				dmas = <&sdma 33 4 0>, <&sdma 34 4 0>;
				dma-names = "rx", "tx";
				status = "disabled";
			};
		};

		ipu1: ipu@02400000 {
			#address-cells = <1>;
			#size-cells = <0>;
			compatible = "fsl,imx6q-ipu";
			reg = <0x02400000 0x400000>;
			interrupts = <0 6 IRQ_TYPE_LEVEL_HIGH>,
				     <0 5 IRQ_TYPE_LEVEL_HIGH>;
			clocks = <&clks IMX6QDL_CLK_IPU1>,
				 <&clks IMX6QDL_CLK_IPU1_DI0>, <&clks IMX6QDL_CLK_IPU1_DI1>,
				 <&clks IMX6QDL_CLK_IPU1_DI0_SEL>, <&clks IMX6QDL_CLK_IPU1_DI1_SEL>,
				 <&clks IMX6QDL_CLK_LDB_DI0>, <&clks IMX6QDL_CLK_LDB_DI1>;
			clock-names = "bus",
				      "di0", "di1",
				      "di0_sel", "di1_sel",
				      "ldb_di0", "ldb_di1";
			resets = <&src 2>;
			bypass_reset = <0>;

			ipu1_csi0: port@0 {
				reg = <0>;

				ipu1_csi0_from_ipu1_csi0_mux: endpoint {
					remote-endpoint = <&ipu1_csi0_mux_to_ipu1_csi0>;
				};
			};

			ipu1_csi1: port@1 {
				reg = <1>;
			};

			ipu1_di0: port@2 {
				#address-cells = <1>;
				#size-cells = <0>;
				reg = <2>;

				ipu1_di0_disp0: disp0-endpoint {
				};

				ipu1_di0_hdmi: hdmi-endpoint {
					remote-endpoint = <&hdmi_mux_0>;
				};

				ipu1_di0_mipi: mipi-endpoint {
					remote-endpoint = <&mipi_mux_0>;
				};

				ipu1_di0_lvds0: lvds0-endpoint {
					remote-endpoint = <&lvds0_mux_0>;
				};

				ipu1_di0_lvds1: lvds1-endpoint {
					remote-endpoint = <&lvds1_mux_0>;
				};
			};

			ipu1_di1: port@3 {
				#address-cells = <1>;
				#size-cells = <0>;
				reg = <3>;

				ipu1_di1_disp1: disp1-endpoint {
				};

				ipu1_di1_hdmi: hdmi-endpoint {
					remote-endpoint = <&hdmi_mux_1>;
				};

				ipu1_di1_mipi: mipi-endpoint {
					remote-endpoint = <&mipi_mux_1>;
				};

				ipu1_di1_lvds0: lvds0-endpoint {
					remote-endpoint = <&lvds0_mux_1>;
				};

				ipu1_di1_lvds1: lvds1-endpoint {
					remote-endpoint = <&lvds1_mux_1>;
				};
			};
		};
	};
};


/ {
	aliases {
		i2c3 = &i2c4;
	};

	cpus {
		#address-cells = <1>;
		#size-cells = <0>;

		cpu@0 {
			compatible = "arm,cortex-a9";
			device_type = "cpu";
			reg = <0>;
			next-level-cache = <&L2>;
			operating-points = <
				/* kHz    uV */
				996000  1250000
				792000  1175000
				396000  1150000
			>;
			fsl,soc-operating-points = <
				/* ARM kHz  SOC-PU uV */
				996000	1175000
				792000	1175000
				396000	1175000
			>;
			clock-latency = <61036>; /* two CLK32 periods */
			clocks = <&clks IMX6QDL_CLK_ARM>,
				 <&clks IMX6QDL_CLK_PLL2_PFD2_396M>,
				 <&clks IMX6QDL_CLK_STEP>,
				 <&clks IMX6QDL_CLK_PLL1_SW>,
				 <&clks IMX6QDL_CLK_PLL1_SYS>,
				 <&clks IMX6QDL_CLK_PLL1>,
				 <&clks IMX6QDL_PLL1_BYPASS>,
				 <&clks IMX6QDL_PLL1_BYPASS_SRC>;
			clock-names = "arm", "pll2_pfd2_396m", "step",
				      "pll1_sw", "pll1_sys", "pll1",
				      "pll1_bypass", "pll1_bypass_src";
			arm-supply = <&reg_arm>;
			pu-supply = <&reg_pu>;
			soc-supply = <&reg_soc>;
		};

		cpu@1 {
			compatible = "arm,cortex-a9";
			device_type = "cpu";
			reg = <1>;
			next-level-cache = <&L2>;
		};
	};

	reserved-memory {
		#address-cells = <1>;
		#size-cells = <1>;
		ranges;

		/* global autoconfigured region for contiguous allocations */
		linux,cma {
			compatible = "shared-dma-pool";
			reusable;
			size = <0x14000000>;
			linux,cma-default;
		};
	};

	soc {
		busfreq {
			compatible = "fsl,imx_busfreq";
			clocks = <&clks IMX6QDL_CLK_PLL2_BUS>, <&clks IMX6QDL_CLK_PLL2_PFD2_396M>,
				<&clks IMX6QDL_CLK_PLL2_198M>, <&clks IMX6QDL_CLK_ARM>,
				<&clks IMX6QDL_CLK_PLL3_USB_OTG>, <&clks IMX6QDL_CLK_PERIPH>,
				<&clks IMX6QDL_CLK_PERIPH_PRE>, <&clks IMX6QDL_CLK_PERIPH_CLK2>,
				<&clks IMX6QDL_CLK_PERIPH_CLK2_SEL>, <&clks IMX6QDL_CLK_OSC>,
				<&clks IMX6QDL_CLK_AXI_ALT_SEL>, <&clks IMX6QDL_CLK_AXI_SEL> ,
				<&clks IMX6QDL_CLK_PLL3_PFD1_540M>;
			clock-names = "pll2_bus", "pll2_pfd2_396m", "pll2_198m", "arm", "pll3_usb_otg", "periph",
				"periph_pre", "periph_clk2", "periph_clk2_sel", "osc", "axi_alt_sel", "axi_sel", "pll3_pfd1_540m";
			interrupts = <0 107 0x04>, <0 112 0x4>;
			interrupt-names = "irq_busfreq_0", "irq_busfreq_1";
			fsl,max_ddr_freq = <400000000>;
		};

		gpu: gpu@00130000 {
			compatible = "fsl,imx6dl-gpu", "fsl,imx6q-gpu";
			reg = <0x00130000 0x4000>, <0x00134000 0x4000>,
			      <0x10000000 0x0>, <0x0 0x8000000>;
			reg-names = "iobase_3d", "iobase_2d",
				    "phys_baseaddr", "contiguous_mem";
			interrupts = <0 9 IRQ_TYPE_LEVEL_HIGH>,
				     <0 10 IRQ_TYPE_LEVEL_HIGH>;
			interrupt-names = "irq_3d", "irq_2d";
			clocks = <&clks IMX6QDL_CLK_OPENVG_AXI>, <&clks IMX6QDL_CLK_GPU3D_AXI>,
				 <&clks IMX6QDL_CLK_GPU2D_CORE>, <&clks IMX6QDL_CLK_GPU3D_CORE>,
				 <&clks IMX6QDL_CLK_DUMMY>;
			clock-names = "gpu2d_axi_clk", "gpu3d_axi_clk",
				      "gpu2d_clk", "gpu3d_clk",
				      "gpu3d_shader_clk";
			resets = <&src 0>, <&src 3>;
			reset-names = "gpu3d", "gpu2d";
			power-domains = <&pd_pu>;
		};

		ocram: sram@00905000 {
			compatible = "mmio-sram";
			reg = <0x00905000 0x1B000>;
			clocks = <&clks IMX6QDL_CLK_OCRAM>;
		};

		ocram_optee: sram@00918000 {
			compatible = "fsl,optee-lpm-sram";
			reg = <0x00918000 0x8000>;
			overw_reg = <&ocram 0x00905000 0x13000>;
		};

		aips1: aips-bus@02000000 {
			iomuxc: iomuxc@020e0000 {
				compatible = "fsl,imx6dl-iomuxc";
			};

			dcic2: dcic@020e8000 {
				clocks = <&clks IMX6QDL_CLK_DCIC1 >,
						<&clks IMX6QDL_CLK_DCIC2>; /* DCIC2 depend on DCIC1 clock in imx6dl*/
				clock-names = "dcic", "disp-axi";
			};

			pxp: pxp@020f0000 {
				compatible = "fsl,imx6dl-pxp-dma";
				reg = <0x020f0000 0x4000>;
				interrupts = <0 98 IRQ_TYPE_LEVEL_HIGH>;
				clocks = <&clks IMX6QDL_CLK_IPU2>, <&clks IMX6QDL_CLK_DUMMY>;
				clock-names = "pxp-axi", "disp-axi";
				status = "disabled";
			};

			epdc: epdc@020f4000 {
				compatible = "fsl,imx6dl-epdc";
				reg = <0x020f4000 0x4000>;
				interrupts = <0 97 IRQ_TYPE_LEVEL_HIGH>;
				clocks = <&clks IMX6QDL_CLK_IPU2>, <&clks IMX6QDL_CLK_IPU2_DI1>;
				clock-names = "epdc_axi", "epdc_pix";
				status = "disabled";
			};

			lcdif: lcdif@020f8000 {
				reg = <0x020f8000 0x4000>;
				interrupts = <0 39 IRQ_TYPE_LEVEL_HIGH>;
			};
		};

		aips2: aips-bus@02100000 {
			mipi_dsi: mipi@021e0000 {
				compatible = "fsl,imx6dl-mipi-dsi";
				reg = <0x021e0000 0x4000>;
				interrupts = <0 102 0x04>;
				gpr = <&gpr>;
				clocks = <&clks IMX6QDL_CLK_HSI_TX>, <&clks IMX6QDL_CLK_VIDEO_27M>;
				clock-names = "mipi_pllref_clk", "mipi_cfg_clk";
				status = "disabled";
			};

			i2c4: i2c@021f8000 {
				#address-cells = <1>;
				#size-cells = <0>;
				compatible = "fsl,imx6q-i2c", "fsl,imx21-i2c";
				reg = <0x021f8000 0x4000>;
				interrupts = <0 35 IRQ_TYPE_LEVEL_HIGH>;
				clocks = <&clks IMX6DL_CLK_I2C4>;
				status = "disabled";
			};
		};
	};

	capture-subsystem {
		compatible = "fsl,imx-capture-subsystem";
		ports = <&ipu1_csi0>, <&ipu1_csi1>;
	};

	display-subsystem {
		compatible = "fsl,imx-display-subsystem";
		ports = <&ipu1_di0>, <&ipu1_di1>;
	};

	gpu-subsystem {
		compatible = "fsl,imx-gpu-subsystem";
		cores = <&gpu_2d>, <&gpu_3d>;
	};
};

&gpio1 {
	gpio-ranges = <&iomuxc  0 131 2>, <&iomuxc  2 137 8>, <&iomuxc 10 189 2>,
		      <&iomuxc 12 194 1>, <&iomuxc 13 193 1>, <&iomuxc 14 192 1>,
		      <&iomuxc 15 191 1>, <&iomuxc 16 185 2>, <&iomuxc 18 184 1>,
		      <&iomuxc 19 187 1>, <&iomuxc 20 183 1>, <&iomuxc 21 188 1>,
		      <&iomuxc 22 123 3>, <&iomuxc 25 121 1>, <&iomuxc 26 127 1>,
		      <&iomuxc 27 126 1>, <&iomuxc 28 128 1>, <&iomuxc 29 130 1>,
		      <&iomuxc 30 129 1>, <&iomuxc 31 122 1>;
};

&gpio2 {
	gpio-ranges = <&iomuxc  0 161 8>, <&iomuxc  8 208 8>, <&iomuxc 16  74 1>,
		      <&iomuxc 17  73 1>, <&iomuxc 18  72 1>, <&iomuxc 19  71 1>,
		      <&iomuxc 20  70 1>, <&iomuxc 21  69 1>, <&iomuxc 22  68 1>,
		      <&iomuxc 23  79 2>, <&iomuxc 25 118 2>, <&iomuxc 27 117 1>,
		      <&iomuxc 28 113 4>;
};

&gpio3 {
	gpio-ranges = <&iomuxc  0 97  2>, <&iomuxc 2 105 8>, <&iomuxc 10 99 6>,
		      <&iomuxc 16 81 16>;
};

&gpio4 {
	gpio-ranges = <&iomuxc  5 136 1>, <&iomuxc  6 145 1>, <&iomuxc  7 150 1>,
		      <&iomuxc  8 146 1>, <&iomuxc  9 151 1>, <&iomuxc 10 147 1>,
		      <&iomuxc 11 152 1>, <&iomuxc 12 148 1>, <&iomuxc 13 153 1>,
		      <&iomuxc 14 149 1>, <&iomuxc 15 154 1>, <&iomuxc 16  39 7>,
		      <&iomuxc 23  56 1>, <&iomuxc 24  61 7>, <&iomuxc 31  46 1>;
};

&gpio5 {
	gpio-ranges = <&iomuxc  0 120 1>, <&iomuxc  2 77 1>, <&iomuxc  4 76 1>,
		      <&iomuxc  5  47 9>, <&iomuxc 14 57 4>, <&iomuxc 18 37 1>,
		      <&iomuxc 19  36 1>, <&iomuxc 20 35 1>, <&iomuxc 21 38 1>,
		      <&iomuxc 22  29 6>, <&iomuxc 28 19 4>;
};

&gpio6 {
	gpio-ranges = <&iomuxc  0  23 6>, <&iomuxc  6  75 1>, <&iomuxc  7 156 1>,
		      <&iomuxc  8 155 1>, <&iomuxc  9 170 1>, <&iomuxc 10 169 1>,
		      <&iomuxc 11 157 1>, <&iomuxc 14 158 3>, <&iomuxc 17 204 1>,
		      <&iomuxc 18 203 1>, <&iomuxc 19 182 1>, <&iomuxc 20 177 4>,
		      <&iomuxc 24 175 1>, <&iomuxc 25 171 1>, <&iomuxc 26 181 1>,
		      <&iomuxc 27 172 3>, <&iomuxc 30 176 1>, <&iomuxc 31  78 1>;
};

&gpio7 {
	gpio-ranges = <&iomuxc 0 202 1>, <&iomuxc  1 201 1>, <&iomuxc  2 196 1>,
		      <&iomuxc 3 195 1>, <&iomuxc  4 197 4>, <&iomuxc  8 205 1>,
		      <&iomuxc 9 207 1>, <&iomuxc 10 206 1>, <&iomuxc 11 133 3>;
};

&gpr {
	ipu1_csi0_mux: ipu1_csi0_mux@34 {
		compatible = "video-mux";
		mux-controls = <&mux 0>;
		#address-cells = <1>;
		#size-cells = <0>;

		port@0 {
			reg = <0>;

			ipu1_csi0_mux_from_mipi_vc0: endpoint {
				remote-endpoint = <&mipi_vc0_to_ipu1_csi0_mux>;
			};
		};

		port@1 {
			reg = <1>;

			ipu1_csi0_mux_from_mipi_vc1: endpoint {
				remote-endpoint = <&mipi_vc1_to_ipu1_csi0_mux>;
			};
		};

		port@2 {
			reg = <2>;

			ipu1_csi0_mux_from_mipi_vc2: endpoint {
				remote-endpoint = <&mipi_vc2_to_ipu1_csi0_mux>;
			};
		};

		port@3 {
			reg = <3>;

			ipu1_csi0_mux_from_mipi_vc3: endpoint {
				remote-endpoint = <&mipi_vc3_to_ipu1_csi0_mux>;
			};
		};

		port@4 {
			reg = <4>;

			ipu1_csi0_mux_from_parallel_sensor: endpoint {
			};
		};

		port@5 {
			reg = <5>;

			ipu1_csi0_mux_to_ipu1_csi0: endpoint {
				remote-endpoint = <&ipu1_csi0_from_ipu1_csi0_mux>;
			};
		};
	};

	ipu1_csi1_mux: ipu1_csi1_mux@34 {
		compatible = "video-mux";
		mux-controls = <&mux 1>;
		#address-cells = <1>;
		#size-cells = <0>;

		port@0 {
			reg = <0>;

			ipu1_csi1_mux_from_mipi_vc0: endpoint {
				remote-endpoint = <&mipi_vc0_to_ipu1_csi1_mux>;
			};
		};

		port@1 {
			reg = <1>;

			ipu1_csi1_mux_from_mipi_vc1: endpoint {
				remote-endpoint = <&mipi_vc1_to_ipu1_csi1_mux>;
			};
		};

		port@2 {
			reg = <2>;

			ipu1_csi1_mux_from_mipi_vc2: endpoint {
				remote-endpoint = <&mipi_vc2_to_ipu1_csi1_mux>;
			};
		};

		port@3 {
			reg = <3>;

			ipu1_csi1_mux_from_mipi_vc3: endpoint {
				remote-endpoint = <&mipi_vc3_to_ipu1_csi1_mux>;
			};
		};

		port@4 {
			reg = <4>;

			ipu1_csi1_mux_from_parallel_sensor: endpoint {
			};
		};

		port@5 {
			reg = <5>;

			ipu1_csi1_mux_to_ipu1_csi1: endpoint {
				remote-endpoint = <&ipu1_csi1_from_ipu1_csi1_mux>;
			};
		};
	};
};

&gpt {
	compatible = "fsl,imx6dl-gpt";
};

&hdmi {
	compatible = "fsl,imx6dl-hdmi";
};

&ipu1_csi1 {
	ipu1_csi1_from_ipu1_csi1_mux: endpoint {
		remote-endpoint = <&ipu1_csi1_mux_to_ipu1_csi1>;
	};
};

&ldb {
	compatible = "fsl,imx6dl-ldb", "fsl,imx53-ldb";
	clocks = <&clks IMX6QDL_CLK_LDB_DI0>, <&clks IMX6QDL_CLK_LDB_DI1>,
		 <&clks IMX6QDL_CLK_IPU1_DI0_SEL>, <&clks IMX6QDL_CLK_IPU1_DI1_SEL>,
		 <&clks IMX6QDL_CLK_IPU2_DI0_SEL>,
		 <&clks IMX6QDL_CLK_LDB_DI0_DIV_3_5>, <&clks IMX6QDL_CLK_LDB_DI1_DIV_3_5>,
		 <&clks IMX6QDL_CLK_LDB_DI0_DIV_7>, <&clks IMX6QDL_CLK_LDB_DI1_DIV_7>,
		 <&clks IMX6QDL_CLK_LDB_DI0_DIV_SEL>, <&clks IMX6QDL_CLK_LDB_DI1_DIV_SEL>;
	clock-names = "ldb_di0", "ldb_di1",
		      "di0_sel", "di1_sel",
		      "di2_sel",
		      "ldb_di0_div_3_5", "ldb_di1_div_3_5",
		      "ldb_di0_div_7", "ldb_di1_div_7",
		      "ldb_di0_div_sel", "ldb_di1_div_sel";
};

&mipi_csi {
	port@1 {
		reg = <1>;
		#address-cells = <1>;
		#size-cells = <0>;

		mipi_vc0_to_ipu1_csi0_mux: endpoint@0 {
			remote-endpoint = <&ipu1_csi0_mux_from_mipi_vc0>;
		};

		mipi_vc0_to_ipu1_csi1_mux: endpoint@1 {
			remote-endpoint = <&ipu1_csi1_mux_from_mipi_vc0>;
		};
	};

	port@2 {
		reg = <2>;
		#address-cells = <1>;
		#size-cells = <0>;

		mipi_vc1_to_ipu1_csi0_mux: endpoint@0 {
			remote-endpoint = <&ipu1_csi0_mux_from_mipi_vc1>;
		};

		mipi_vc1_to_ipu1_csi1_mux: endpoint@1 {
			remote-endpoint = <&ipu1_csi1_mux_from_mipi_vc1>;
		};
	};

	port@3 {
		reg = <3>;
		#address-cells = <1>;
		#size-cells = <0>;

		mipi_vc2_to_ipu1_csi0_mux: endpoint@0 {
			remote-endpoint = <&ipu1_csi0_mux_from_mipi_vc2>;
		};

		mipi_vc2_to_ipu1_csi1_mux: endpoint@1 {
			remote-endpoint = <&ipu1_csi1_mux_from_mipi_vc2>;
		};
	};

	port@4 {
		reg = <4>;
		#address-cells = <1>;
		#size-cells = <0>;

		mipi_vc3_to_ipu1_csi0_mux: endpoint@0 {
			remote-endpoint = <&ipu1_csi0_mux_from_mipi_vc3>;
		};

		mipi_vc3_to_ipu1_csi1_mux: endpoint@1 {
			remote-endpoint = <&ipu1_csi1_mux_from_mipi_vc3>;
		};
	};
};

&mux {
	mux-reg-masks = <0x34 0x00000007>, /* IPU_CSI0_MUX */
			<0x34 0x00000038>, /* IPU_CSI1_MUX */
			<0x0c 0x0000000c>, /* HDMI_MUX_CTL */
			<0x0c 0x000000c0>, /* LVDS0_MUX_CTL */
			<0x0c 0x00000300>, /* LVDS1_MUX_CTL */
			<0x28 0x00000003>, /* DCIC1_MUX_CTL */
			<0x28 0x0000000c>; /* DCIC2_MUX_CTL */
};

&vpu {
	compatible = "fsl,imx6dl-vpu", "cnm,coda960";
};

&vpu_fsl {
	iramsize = <0>;
};


/ {
	aliases {
		mxcfb0 = &mxcfb1;
		mxcfb1 = &mxcfb2;
		mxcfb2 = &mxcfb3;
		mxcfb3 = &mxcfb4;
	};

	chosen {
		stdout-path = &uart1;
	};

	memory: memory {
		reg = <0x10000000 0x40000000>;
	};

	regulators {
		compatible = "simple-bus";
		#address-cells = <1>;
		#size-cells = <0>;

		reg_usb_otg_vbus: regulator@0 {
			compatible = "regulator-fixed";
			reg = <0>;
			regulator-name = "usb_otg_vbus";
			regulator-min-microvolt = <5000000>;
			regulator-max-microvolt = <5000000>;
		};

		reg_usb_h1_vbus: regulator@1 {
			compatible = "regulator-fixed";
			reg = <1>;
			regulator-name = "usb_h1_vbus";
			regulator-min-microvolt = <5000000>;
			regulator-max-microvolt = <5000000>;
		};

		reg_audio: regulator@2 {
			compatible = "regulator-fixed";
			reg = <2>;
			regulator-name = "tlv320aic3x-supply";
			enable-active-high;
		};

		reg_3p3v: regulator@3 {
			compatible = "regulator-fixed";
			regulator-name = "3P3V";
			regulator-min-microvolt = <3300000>;
			regulator-max-microvolt = <3300000>;
			regulator-always-on;
		};

		touch_3v3_regulator: touch_3v3_regulator {
			compatible = "regulator-fixed";
			regulator-name = "touch_3v3_supply";
			regulator-always-on;
			status = "okay";
		};
	};

	wlan_en_reg: fixedregulator@2 {
		compatible = "regulator-fixed";
		regulator-name = "wlan-en-regulator";
		regulator-min-microvolt = <1800000>;
		regulator-max-microvolt = <1800000>;

		/* WLAN_EN GPIO for this board - Bank5, pin13 */
		gpio = <&gpio7 8 0>;

		/* WLAN card specific delay */
		startup-delay-us = <70000>;
		enable-active-high;
	};

	sound {
		compatible = "fsl,imx6q-var-som-tlv320aic3x", "fsl,imx-audio-tlv320aic3x";
		model = "tlv320aic3x-audio";
		cpu-dai = <&ssi2>;
		audio-codec = <&codec>;
		audio-routing =
			/* Headphone connected to HPLOUT, HPROUT */
			"Headphone Jack",	"HPLOUT",
			"Headphone Jack",	"HPROUT",
			"Line In Jack",		"LINE1L",
			"Line In Jack",		"LINE1R",
			"Mic Jack",		"DMIC";
		mux-int-port = <2>;
		mux-ext-port = <3>;
	};

	sound-hdmi {
		compatible = "fsl,imx6q-audio-hdmi",
			     "fsl,imx-audio-hdmi";
		model = "imx-audio-hdmi";
		hdmi-controller = <&hdmi_audio>;
	};

	mxcfb1: fb@0 {
		compatible = "fsl,mxc_sdc_fb";
		disp_dev = "ldb";
		mode_str ="CLAA-WVGA";
		default_bpp = <32>;
		interface_pix_fmt = "RGB24";
		int_clk = <0>;
		late_init = <0>;
		status = "okay";
	};

	mxcfb2: fb@1 {
		compatible = "fsl,mxc_sdc_fb";
		disp_dev = "hdmi";
		interface_pix_fmt = "RGB24";
		mode_str ="1920x1080M@60";
		default_bpp = <32>;
		int_clk = <0>;
		late_init = <0>;
		status = "okay";
	};

	mxcfb3: fb@2 {
		compatible = "fsl,mxc_sdc_fb";
		disp_dev = "lcd";
		interface_pix_fmt = "RGB565";
		mode_str ="CLAA-WVGA";
		default_bpp = <16>;
		int_clk = <0>;
		late_init = <0>;
		status = "disabled";
	};

	mxcfb4: fb@3 {
		compatible = "fsl,mxc_sdc_fb";
		disp_dev = "ldb";
		interface_pix_fmt = "RGB666";
		mode_str ="CLAA-WVGA";
		default_bpp = <16>;
		int_clk = <0>;
		late_init = <0>;
		status = "disabled";
	};

	backlight {
		compatible = "pwm-backlight";
		pwms = <&pwm2 0 50000>;
		brightness-levels = <0 4 8 16 32 64 128 248>;
		default-brightness-level = <7>;
		status = "okay";
	};

	v4l2_cap_0 {
		compatible = "fsl,imx6q-v4l2-capture";
		ipu_id = <0>;
		csi_id = <1>;
		mclk_source = <0>;
		status = "okay";
	};

	v4l2_out {
		compatible = "fsl,mxc_v4l2_output";
		status = "okay";
	};
};

&audmux {
	pinctrl-names = "default";
	pinctrl-0 = <&pinctrl_audmux_2>;
	status = "okay";
};

&reg_arm {
	vin-supply = <&sw1a_reg>;
};

&reg_pu {
	vin-supply = <&sw1c_reg>;
};

&reg_soc {
	vin-supply = <&sw1c_reg>;
};

&clks {
	assigned-clocks = <&clks IMX6QDL_CLK_LDB_DI0_SEL>,
			  <&clks IMX6QDL_CLK_LDB_DI1_SEL>;
	assigned-clock-parents = <&clks IMX6QDL_CLK_PLL2_PFD0_352M>,
				 <&clks IMX6QDL_CLK_PLL2_PFD0_352M>;
};

&ecspi3 {
	fsl,spi-num-chipselects = <1>;
	pinctrl-names = "default", "sleep";
	pinctrl-0 = <&pinctrl_ecspi3_1>;
	pinctrl-1 = <&pinctrl_ecspi3_1_sleep>;
	cs-gpios = <&gpio4 24 0>;
	status = "okay";
};

&fec {
	pinctrl-names = "default";
	pinctrl-0 = <&pinctrl_enet_4>;
	phy-mode = "rgmii";
	phy-reset-gpios = <&gpio1 25 0>;
	phy-reset-duration=<100>;
	phy-reset-on-resume;
	status = "okay";
};

&gpc {
	/* use ldo-bypass, u-boot will check it and configure */
	fsl,ldo-bypass = <1>;
};

&dcic1 {
	dcic_id = <0>;
	dcic_mux = "dcic-hdmi";
	status = "okay";
};

&dcic2 {
	dcic_id = <1>;
	dcic_mux = "dcic-lvds1";
	status = "okay";
};

&hdmi_audio {
	status = "okay";
};

&hdmi_cec {
	pinctrl-names = "default";
	pinctrl-0 = <&pinctrl_hdmi_cec>;
	status = "okay";
};

&hdmi_core {
	ipu_id = <0>;
	disp_id = <0>;
	status = "okay";
};

&hdmi_video {
	fsl,phy_reg_vlev = <0x0294>;
	fsl,phy_reg_cksymtx = <0x800d>;
	status = "okay";
};

&i2c1 {
	clock-frequency = <100000>;
	pinctrl-names = "default";
	pinctrl-0 = <&pinctrl_i2c1_2>;
	status = "okay";

	ov564x_mipi: ov564x_mipi@3c {
		compatible = "ovti,ov564x_mipi";
		reg = <0x3c>;
		clocks = <&clks 200>;
		clock-names = "csi_mclk";
#if 0
		DOVDD-supply = <&vgen4_reg>; /* 1.8v */
		AVDD-supply = <&vgen3_reg>;  /* 2.8v, rev C board is VGEN3 rev B board is VGEN5 */
		DVDD-supply = <&vgen2_reg>;  /* 1.5v*/
#endif
		pwn-gpios = <&gpio3 13 1>;
		rst-gpios = <&gpio4 10 0>;
		csi_id = <1>;
		mclk = <24000000>;
		mclk_source = <0>;
	};
};

&i2c2 {
	clock-frequency = <100000>;
	pinctrl-names = "default";
	pinctrl-0 = <&pinctrl_i2c2_2>;
	status = "okay";

	hdmi_edid: edid@50 {
		compatible = "fsl,imx6-hdmi-i2c";
		reg = <0x50>;
	};

	codec: tlv320aic3x@1b {
		compatible = "ti,tlv320aic3x";
		reg = <0x1b>;
		clocks = <&clks IMX6QDL_CLK_CKO>;
		clock-names = "clko_clk";
		IOVDD-supply = <&reg_audio>;
		DVDD-supply = <&reg_audio>;
		AVDD-supply = <&reg_audio>;
		DRVDD-supply = <&reg_audio>;
		gpio-reset = <&gpio4 5 1>;
		ai3x-gpio-func = <
			0 /* AIC3X_GPIO1_FUNC_DISABLED */
			5 /* AIC3X_GPIO2_FUNC_DIGITAL_MIC_INPUT */
		>;
	};

	pmic: pfuze100@08 {
		compatible = "fsl,pfuze100";
		reg = <0x08>;

		regulators {
			sw1a_reg: sw1ab {
				regulator-min-microvolt = <300000>;
				regulator-max-microvolt = <1875000>;
				regulator-boot-on;
				regulator-always-on;
				regulator-ramp-delay = <6250>;
			};

			sw1c_reg: sw1c {
				regulator-min-microvolt = <300000>;
				regulator-max-microvolt = <1875000>;
				regulator-boot-on;
				regulator-always-on;
				regulator-ramp-delay = <6250>;
			};

			sw2_reg: sw2 {
				regulator-min-microvolt = <800000>;
				regulator-max-microvolt = <3300000>;
				regulator-boot-on;
				regulator-always-on;
			};

			sw3a_reg: sw3a {
				regulator-min-microvolt = <800000>;
				regulator-max-microvolt = <3950000>;
				regulator-boot-on;
				regulator-always-on;
			};

			sw3b_reg: sw3b {
				regulator-min-microvolt = <800000>;
				regulator-max-microvolt = <3950000>;
				regulator-boot-on;
				regulator-always-on;
			};

			sw4_reg: sw4 {
				regulator-min-microvolt = <800000>;
				regulator-max-microvolt = <3950000>;
			};

			snvs_reg: vsnvs {
				regulator-min-microvolt = <1200000>;
				regulator-max-microvolt = <3000000>;
				regulator-boot-on;
				regulator-always-on;
			};

			vref_reg: vrefddr {
				regulator-boot-on;
				regulator-always-on;
			};

			vgen1_reg: vgen1 {
				regulator-min-microvolt = <800000>;
				regulator-max-microvolt = <1550000>;
			};

			vgen2_reg: vgen2 {
				regulator-min-microvolt = <800000>;
				regulator-max-microvolt = <1550000>;
			};

			vgen3_reg: vgen3 {
				regulator-min-microvolt = <1800000>;
				regulator-max-microvolt = <3300000>;
				regulator-always-on;
				regulator-boot-on;
			};

			vgen4_reg: vgen4 {
				regulator-min-microvolt = <1800000>;
				regulator-max-microvolt = <3300000>;
				regulator-always-on;
				regulator-boot-on;
			};

			vgen5_reg: vgen5 {
				regulator-min-microvolt = <1800000>;
				regulator-max-microvolt = <3300000>;
				regulator-always-on;
				regulator-boot-on;
			};

			vgen6_reg: vgen6 {
				regulator-min-microvolt = <2800000>;
				regulator-max-microvolt = <2800000>;
				regulator-always-on;
				regulator-boot-on;
			};
		};
	};
};

&i2c3 {
	clock-frequency = <100000>;
	pinctrl-names = "default";
	pinctrl-0 = <&pinctrl_i2c3_3>;
	status = "okay";

	/* DS1337 RTC module */
	rtc@0x68 {
		compatible = "dallas,ds1337";
		reg = <0x68>;
	};
};

&iomuxc {
	pinctrl-names = "default";
	pinctrl-0 = <&pinctrl_hog>;

	imx6qdl-var-som-mx6 {

		pinctrl_hog: hoggrp {
			fsl,pins = <
				/* CTW6120 IRQ */
				MX6QDL_PAD_EIM_DA7__GPIO3_IO07 		0x80000000
				/* for Bluetooth/wifi enable */
				MX6QDL_PAD_SD3_DAT6__GPIO6_IO18		0x1b0b1
				/* SDMMC2 CD/WP */
				MX6QDL_PAD_KEY_COL4__GPIO4_IO14		0x80000000
				MX6QDL_PAD_KEY_ROW4__GPIO4_IO15		0x80000000
				/* USBOTG ID pin */
				/*MX6QDL_PAD_GPIO_4__GPIO1_IO04		0x80000000*/
				/* PMIC INT */
				MX6QDL_PAD_GPIO_17__GPIO7_IO12		0x80000000
				/* Wifi Slow Clock */
				MX6QDL_PAD_ENET_RXD0__OSC32K_32K_OUT	0x000b0
				/* Audio Clock */
				MX6QDL_PAD_GPIO_0__CCM_CLKO1		0x130b0
				/* Audio reset */
				MX6QDL_PAD_GPIO_19__GPIO4_IO05		0x178b0
				/* Camera Clock */
				MX6QDL_PAD_GPIO_3__CCM_CLKO2		0x130b0
				/* Resistive touch irq */
				MX6QDL_PAD_DISP0_DAT4__GPIO4_IO25	0x178b0
				/* LVDS Mux External camera/display (out) */
				MX6QDL_PAD_SD4_DAT3__GPIO2_IO11 	0x130B0
			>;
		};

		pinctrl_audmux_2: audmux {
			fsl,pins = <
				MX6QDL_PAD_CSI0_DAT7__AUD3_RXD		0x130b0
				MX6QDL_PAD_CSI0_DAT4__AUD3_TXC		0x130b0
				MX6QDL_PAD_CSI0_DAT5__AUD3_TXD		0x110b0
				MX6QDL_PAD_CSI0_DAT6__AUD3_TXFS		0x130b0
			>;
		};

		pinctrl_enet_4: enetgrp {
			fsl,pins = <
				MX6QDL_PAD_ENET_MDIO__ENET_MDIO		0x1b0b0
				MX6QDL_PAD_ENET_MDC__ENET_MDC		0x1b0b0
				MX6QDL_PAD_RGMII_TXC__RGMII_TXC		0x1b0b0
				MX6QDL_PAD_RGMII_TD0__RGMII_TD0		0x1b0b0
				MX6QDL_PAD_RGMII_TD1__RGMII_TD1		0x1b0b0
				MX6QDL_PAD_RGMII_TD2__RGMII_TD2		0x1b0b0
				MX6QDL_PAD_RGMII_TD3__RGMII_TD3		0x1b0b0
				MX6QDL_PAD_RGMII_TX_CTL__RGMII_TX_CTL	0x1b0b0
				MX6QDL_PAD_ENET_REF_CLK__ENET_TX_CLK	0x1b0b0
				MX6QDL_PAD_RGMII_RXC__RGMII_RXC		0x1b0b0
				MX6QDL_PAD_RGMII_RD0__RGMII_RD0		0x1b0b0
				MX6QDL_PAD_RGMII_RD1__RGMII_RD1		0x1b0b0
				MX6QDL_PAD_RGMII_RD2__RGMII_RD2		0x1b0b0
				MX6QDL_PAD_RGMII_RD3__RGMII_RD3		0x1b0b0
				MX6QDL_PAD_RGMII_RX_CTL__RGMII_RX_CTL	0x1b0b0
			>;
		};

		pinctrl_enet_irq: enetirqgrp {
			fsl,pins = <
				MX6QDL_PAD_GPIO_6__ENET_IRQ		0x000b1
			>;
		};

		pinctrl_hdmi_cec: hdmicecgrp {
			fsl,pins = <
				MX6QDL_PAD_KEY_ROW2__HDMI_TX_CEC_LINE	0x1f8b0
			>;
		};

		pinctrl_hdmi_hdcp: hdmihdcpgrp {
			fsl,pins = <
				MX6QDL_PAD_KEY_COL3__HDMI_TX_DDC_SCL	0x4001b8b1
				MX6QDL_PAD_KEY_ROW3__HDMI_TX_DDC_SDA	0x4001b8b1
			>;
		};

		pinctrl_i2c1_2: i2c1grp {
			fsl,pins = <
				MX6QDL_PAD_CSI0_DAT8__I2C1_SDA		0x4001b8b1
				MX6QDL_PAD_CSI0_DAT9__I2C1_SCL		0x4001b8b1
			>;
		};

		pinctrl_i2c2_2: i2c2grp {
			fsl,pins = <
				MX6QDL_PAD_KEY_COL3__I2C2_SCL		0x4001b8b1
				MX6QDL_PAD_KEY_ROW3__I2C2_SDA		0x4001b8b1
			>;
		};

		pinctrl_i2c3_3: i2c3grp {
			fsl,pins = <
				MX6QDL_PAD_GPIO_5__I2C3_SCL		0x4001b8b1
				MX6QDL_PAD_GPIO_16__I2C3_SDA		0x4001b8b1
			>;
		};

		pinctrl_ipu1_2: ipu1grp-2 { /* parallel camera */
			fsl,pins = <
				MX6QDL_PAD_CSI0_DAT12__IPU1_CSI0_DATA12		0x80000000
				MX6QDL_PAD_CSI0_DAT13__IPU1_CSI0_DATA13		0x80000000
				MX6QDL_PAD_CSI0_DAT14__IPU1_CSI0_DATA14		0x80000000
				MX6QDL_PAD_CSI0_DAT15__IPU1_CSI0_DATA15		0x80000000
				MX6QDL_PAD_CSI0_DAT16__IPU1_CSI0_DATA16		0x80000000
				MX6QDL_PAD_CSI0_DAT17__IPU1_CSI0_DATA17		0x80000000
				MX6QDL_PAD_CSI0_DAT18__IPU1_CSI0_DATA18		0x80000000
				MX6QDL_PAD_CSI0_DAT19__IPU1_CSI0_DATA19		0x80000000
				MX6QDL_PAD_CSI0_DATA_EN__IPU1_CSI0_DATA_EN	0x80000000
				MX6QDL_PAD_CSI0_PIXCLK__IPU1_CSI0_PIXCLK	0x80000000
				MX6QDL_PAD_CSI0_MCLK__IPU1_CSI0_HSYNC		0x80000000
				MX6QDL_PAD_CSI0_VSYNC__IPU1_CSI0_VSYNC		0x80000000
			>;
		};

		pinctrl_pwm2_1: pwm2grp {
			fsl,pins = <
				MX6QDL_PAD_DISP0_DAT9__PWM2_OUT		0x1b0b1
			>;
		};

		/* Linux Console */
		pinctrl_uart1_1: uart1grp-1 { /* RX/TX only */
			fsl,pins = <
				MX6QDL_PAD_CSI0_DAT10__UART1_TX_DATA	0x1b0b1
				MX6QDL_PAD_CSI0_DAT11__UART1_RX_DATA	0x1b0b1
			>;
		};

		/* Variscite Bluetooth */
		pinctrl_uart2_3: uart2grp-3 { /* RTS/CTS only mode */
			fsl,pins = <
				MX6QDL_PAD_SD3_DAT4__UART2_RX_DATA	0x1b0b1
				MX6QDL_PAD_SD3_DAT5__UART2_TX_DATA	0x1b0b1
				MX6QDL_PAD_EIM_D28__UART2_CTS_B		0x1b0b1
				MX6QDL_PAD_EIM_D29__UART2_RTS_B		0x1b0b1
			>;
		};

		/* Variscite Uart2 support */
		pinctrl_uart3_2: uart3grp-2 {	/* RX/TX RTS/CTS */
			fsl,pins = <
				MX6QDL_PAD_EIM_D25__UART3_RX_DATA	0x1b0b1
				MX6QDL_PAD_EIM_D24__UART3_TX_DATA	0x1b0b1
				MX6QDL_PAD_EIM_D23__UART3_CTS_B		0x1b0b1
				MX6QDL_PAD_EIM_EB3__UART3_RTS_B		0x1b0b1
			>;
		};

		pinctrl_usbotg_var: usbotggrp-3 {
			fsl,pins = <
				MX6QDL_PAD_GPIO_4__GPIO1_IO04 		0x17059
			>;
		};

		pinctrl_usdhc1_1: usdhc1grp {
			fsl,pins = <
				MX6QDL_PAD_SD1_CMD__SD1_CMD		0x17071
				MX6QDL_PAD_SD1_CLK__SD1_CLK		0x10071
				MX6QDL_PAD_SD1_DAT0__SD1_DATA0		0x17071
				MX6QDL_PAD_SD1_DAT1__SD1_DATA1		0x17071
				MX6QDL_PAD_SD1_DAT2__SD1_DATA2		0x17071
				MX6QDL_PAD_SD1_DAT3__SD1_DATA3		0x17071
			>;
		};

		pinctrl_usdhc2_2: usdhc2grp {
			fsl,pins = <
				MX6QDL_PAD_SD2_CMD__SD2_CMD		0x17059
				MX6QDL_PAD_SD2_CLK__SD2_CLK		0x10059
				MX6QDL_PAD_SD2_DAT0__SD2_DATA0		0x17059
				MX6QDL_PAD_SD2_DAT1__SD2_DATA1		0x17059
				MX6QDL_PAD_SD2_DAT2__SD2_DATA2		0x17059
				MX6QDL_PAD_SD2_DAT3__SD2_DATA3		0x17059
			>;
		};

		pinctrl_usdhc3_2: usdhc3grp {
			fsl,pins = <
				MX6QDL_PAD_SD3_CMD__SD3_CMD		0x17069
				MX6QDL_PAD_SD3_CLK__SD3_CLK		0x10069
				MX6QDL_PAD_SD3_DAT0__SD3_DATA0		0x17069
				MX6QDL_PAD_SD3_DAT1__SD3_DATA1		0x17069
				MX6QDL_PAD_SD3_DAT2__SD3_DATA2		0x17069
				MX6QDL_PAD_SD3_DAT3__SD3_DATA3		0x17069
				MX6QDL_PAD_SD3_DAT7__GPIO6_IO17		0x13059   /* Reserve two pins from sd1 for wl8 gpio, this is pulled low at reset for WL_EN */
				MX6QDL_PAD_SD3_RST__GPIO7_IO08		0x13059   /* this is for wl_irq which driver will configure as an input with a pull down */
			>;
		};

		pinctrl_usdhc3_2_100mhz: usdhc3grp-100mhz {
			fsl,pins = <
				MX6QDL_PAD_SD3_CMD__SD3_CMD		0x170B9
				MX6QDL_PAD_SD3_CLK__SD3_CLK		0x100B9
				MX6QDL_PAD_SD3_DAT0__SD3_DATA0		0x170B9
				MX6QDL_PAD_SD3_DAT1__SD3_DATA1		0x170B9
				MX6QDL_PAD_SD3_DAT2__SD3_DATA2		0x170B9
				MX6QDL_PAD_SD3_DAT3__SD3_DATA3		0x170B9
				MX6QDL_PAD_SD3_DAT7__GPIO6_IO17		0x130B9   /* reserve two pins from sd1 for wl8 gpio, this is pulled low at reset for WL_EN */
				MX6QDL_PAD_SD3_RST__GPIO7_IO08		0x130B9   /* this is for wl_irq which driver will configure as an input with a pull down */
			>;
		};

		pinctrl_usdhc3_2_200mhz: usdhc3grp-200mhz {
			fsl,pins = <
				MX6QDL_PAD_SD3_CMD__SD3_CMD		0x170F9
				MX6QDL_PAD_SD3_CLK__SD3_CLK		0x100F9
				MX6QDL_PAD_SD3_DAT0__SD3_DATA0		0x170F9
				MX6QDL_PAD_SD3_DAT1__SD3_DATA1		0x170F9
				MX6QDL_PAD_SD3_DAT2__SD3_DATA2		0x170F9
				MX6QDL_PAD_SD3_DAT3__SD3_DATA3		0x170F9
				MX6QDL_PAD_SD3_DAT7__GPIO6_IO17		0x130F9   /* reserve two pins from sd1 for wl8 gpio, this is pulled low at reset for WL_EN */
				MX6QDL_PAD_SD3_RST__GPIO7_IO08		0x130F9   /* this is for wl_irq which driver will configure as an input with a pull down */
			>;
		};

		pinctrl_gpmi_nand_v1: gpmi-nand-1 {
			fsl,pins = <
				MX6QDL_PAD_NANDF_CLE__NAND_CLE		0xb0b1
				MX6QDL_PAD_NANDF_ALE__NAND_ALE		0xb0b1
				MX6QDL_PAD_NANDF_CS0__NAND_CE0_B	0xb0b1
				MX6QDL_PAD_NANDF_CS1__NAND_CE1_B	0xb0b1
				MX6QDL_PAD_NANDF_RB0__NAND_READY_B	0xb0b1
				MX6QDL_PAD_NANDF_D0__NAND_DATA00	0xb0b1
				MX6QDL_PAD_NANDF_D1__NAND_DATA01	0xb0b1
				MX6QDL_PAD_NANDF_D2__NAND_DATA02	0xb0b1
				MX6QDL_PAD_NANDF_D3__NAND_DATA03	0xb0b1
				MX6QDL_PAD_NANDF_D4__NAND_DATA04	0xb0b1
				MX6QDL_PAD_NANDF_D5__NAND_DATA05	0xb0b1
				MX6QDL_PAD_NANDF_D6__NAND_DATA06	0xb0b1
				MX6QDL_PAD_NANDF_D7__NAND_DATA07	0xb0b1
				MX6QDL_PAD_SD4_CMD__NAND_RE_B		0xb0b1
				MX6QDL_PAD_SD4_CLK__NAND_WE_B		0xb0b1
				MX6QDL_PAD_NANDF_WP_B__NAND_WP_B	0xb0b1
			>;
		};

		pinctrl_ecspi3_1: ecspi3grp {
			fsl,pins = <
				MX6QDL_PAD_DISP0_DAT2__ECSPI3_MISO	0x100b1
				MX6QDL_PAD_DISP0_DAT1__ECSPI3_MOSI	0x100b1
				MX6QDL_PAD_DISP0_DAT0__ECSPI3_SCLK	0x100b1
				MX6QDL_PAD_DISP0_DAT3__GPIO4_IO24	0x178b0 /* CS */
			>;
		};

		pinctrl_ecspi3_1_sleep: ecspi3sleepgrp {
			fsl,pins = <
				MX6QDL_PAD_DISP0_DAT2__GPIO4_IO23	0x178b0
				MX6QDL_PAD_DISP0_DAT1__GPIO4_IO22	0x178b0
				MX6QDL_PAD_DISP0_DAT0__GPIO4_IO21	0x178b0
				MX6QDL_PAD_DISP0_DAT3__GPIO4_IO24	0x178b0 /* CS */
			>;
		};

		pinctrl_flexcan1_3: flexcan1grp {
			fsl,pins = <
				MX6QDL_PAD_GPIO_7__FLEXCAN1_TX		0x80000000
				MX6QDL_PAD_GPIO_8__FLEXCAN1_RX		0x80000000
			>;
		};

	};
};

&mipi_csi {
	status = "okay";
	ipu_id = <0>;
	csi_id = <1>;
	v_channel = <0>;
	lanes = <2>;
};

&pcie {
	reset-gpio    = <&gpio5 13 0>;	/* gpio pin num of power good signal */
	wake-up-gpio  = <&gpio3 22 1>;	/* gpio pin num of incoming wakeup signal */
	status = "disabled";
};

&pwm2 {
	pinctrl-names = "default";
	pinctrl-0 = <&pinctrl_pwm2_1>;
	status = "okay";
};

&ssi2 {
	fsl,mode = "i2s-slave";
	status = "okay";
};

&snvs_poweroff {
	status = "okay";
};

/* Console Uart */
&uart1 {
	pinctrl-names = "default";
	pinctrl-0 = <&pinctrl_uart1_1>;
	status = "okay";
};

/* Bluetooth Uart */
&uart2 {
	pinctrl-names = "default";
	pinctrl-0 = <&pinctrl_uart2_3>;
	uart-has-rtscts;
	status = "okay";
};

/* ttymxc2 UART */
&uart3 {
	pinctrl-names = "default";
	pinctrl-0 = <&pinctrl_uart3_2>;
	uart-has-rtscts;
	status = "okay";
};

&can1 {
	pinctrl-names = "default";
	pinctrl-0 = <&pinctrl_flexcan1_3>;
	status = "okay";
};

&gpmi {
	pinctrl-names = "default";
	pinctrl-0 = <&pinctrl_gpmi_nand_v1>;
	fsl,legacy-bch-geometry;
	status = "okay";

	/* a 2 MiB partition */
	partition@0 {
		label = "spl";
		reg = <0x00000000 0x00200000>;
	};

	/* a 2 MiB partition */
	partition@1 {
		label = "bootloader";
		reg = <0x00200000 0x00200000>;
	};

	/* an 8 MiB partition */
	partition@2 {
		label = "kernel";
		reg = <0x00400000 0x00800000>;
	};

	/* a 1012 MiB partition */
	partition@3 {
		label = "rootfs";
		reg = <0x00c00000 0x3f400000>;
	};
};

&usbh1 {
	vbus-supply = <&reg_usb_h1_vbus>;
	status = "okay";
};

&usbotg {
	vbus-supply = <&reg_usb_otg_vbus>;
	pinctrl-names = "default";
	pinctrl-0 = <&pinctrl_usbotg_var>;
	disable-over-current;
	/* dr_mode: One of "host", "peripheral" or "otg". Defaults to "otg" */
	dr_mode = "host";
	srp-disable;
	hnp-disable;
	adp-disable;
	status = "okay";
};

&usbphy1 {
	tx-d-cal = <0x5>;
};

&usbphy2 {
	tx-d-cal = <0x5>;
};

&usdhc1 {	/* uSDHC1, eMMC */
	pinctrl-names = "default";
	pinctrl-0 = <&pinctrl_usdhc1_1>;
	non-removable;
	keep-power-in-suspend;
	enable-sdio-wakeup;
	status = "okay";
};

&usdhc2 {	/* uSDHC2, MMC/SD card */
	pinctrl-names = "default";
	pinctrl-0 = <&pinctrl_usdhc2_2>;
	cd-gpios = <&gpio4 14 GPIO_ACTIVE_LOW>;
	wp-gpios = <&gpio4 15 GPIO_ACTIVE_HIGH>;
	no-1-8-v;
	keep-power-in-suspend;
	enable-sdio-wakeup;
	status = "okay";
};

&usdhc3 {	/* uSDHC3, TiWi wl1271 7 Wilink8 WL18xx*/
	pinctrl-names = "default", "state_100mhz", "state_200mhz";
	pinctrl-0 = <&pinctrl_usdhc3_2>;
	pinctrl-1 = <&pinctrl_usdhc3_2_100mhz>;
	pinctrl-2 = <&pinctrl_usdhc3_2_200mhz>;
	keep-power-in-suspend;
	enable-sdio-wakeup;
	vmmc-supply = <&wlan_en_reg>;
	bus-width = <4>;
	non-removable;
	cap-power-off-card;
	status = "okay";
	#address-cells = <1>;
	#size-cells = <0>;
	wlcore: wlcore@0 {
		compatible = "ti,wl1835";
		reg = <2>;
		interrupt-parent = <&gpio6>;
		interrupts = <17 IRQ_TYPE_EDGE_RISING>;

		/* if a 12xx card is there, configure the clock to WL12XX_REFCLOCK_38_XTAL */
		ref-clock-frequency = <38400000>;
	};
};

&snvs_rtc {
	status = "disabled";
};


&ldb {
	lvds-channel@0 {
		crtc = "ipu1-di0";
	};

	lvds-channel@1 {
		crtc = "ipu1-di1";
	};
};

&pxp {
	status = "okay";
};

&fec {
	/delete-property/ phy-reset-on-resume;
};

&reg_arm {
	/delete-property/ vin-supply;
};

&reg_pu {
	/delete-property/ vin-supply;
};

&reg_soc {
	/delete-property/ vin-supply;
};

&gpc {
	/* use ldo-enable, u-boot will check it and configure */
	fsl,ldo-bypass = <0>;
};


&iomuxc {
	imx6qdl-var-som-mx6 {
		pinctrl_usbotg_1: usbotggrp-1 {
			fsl,pins = <
				MX6QDL_PAD_GPIO_1__USB_OTG_ID		0x17059
			>;
		};

		/*pinctrl_ft5406_pins: ft5406_pins {
			fsl,pins = <
                MX6QDL_PAD_DISP0_DAT23__GPIO5_IO17	0x1B0B0
			>;
		};*/

		pinctrl_egalax_pins: egalax_pins {
			fsl,pins = <
                MX6QDL_PAD_DISP0_DAT18__GPIO5_IO12  0x1B0B0
                MX6QDL_PAD_DISP0_DAT23__GPIO5_IO17	0x1B080
			>;
		};
	};
};

&i2c3 {
	// touch: ft5x06_ts@38 {
	// 	compatible = "edt,edt-ft5x06";
	// 	reg = <0x38>;
	// 	interrupt-parent = <&gpio5>;
	// 	interrupts = <12 IRQ_TYPE_EDGE_FALLING>;
	// 	touchscreen-size-x = <1024>;
	// 	touchscreen-size-y = <600>;
	// };

	touch: touchscreen@41 {
		compatible = "ilitek,ili251x";
		reg = <0x41>;
		interrupt-parent = <&gpio5>;
		interrupts = <12 IRQ_TYPE_EDGE_FALLING>;
	};
    
    /*touch: egalax_ts@2A {
		compatible = "eeti,exc3000";
		reg = <0x2a>;
        interrupt-parent = <&gpio5>;
		interrupts = <12 IRQ_TYPE_LEVEL_LOW>;
		touchscreen-size-x = <4096>;
		touchscreen-size-y = <4096>;
		//touchscreen-inverted-x;
		//touchscreen-swapped-x-y;	
    }; */   
};

&ldb {
	status = "okay";

	lvds-channel@0 {
		fsl,data-mapping = "spwg";
		fsl,data-width = <24>;
		status = "okay";

		display-timings {
			native-mode = <&timing0>;
			timing0: hsd100pxn1 {
				clock-frequency = <71100000>;
				hactive = <1280>;
				vactive = <800>;
				hback-porch = <100>;
				hfront-porch = <50>;
				vback-porch = <10>;
				vfront-porch = <10>;
				hsync-len = <10>;
				vsync-len = <3>;
			};
		};
	};

	lvds-channel@1 {
        
		crtc = "ipu1-di1";
		fsl,data-mapping = "spwg";
		fsl,data-width = <24>;
		status = "okay";
		primary;

		display-timings {
			native-mode = <&timing0>;
			timing0: hsd100pxn1 {
				clock-frequency = <71100000>;
				hactive = <1280>;
				vactive = <800>;
				hback-porch = <100>;
				hfront-porch = <50>;
				vback-porch = <10>;
				vfront-porch = <10>;
				hsync-len = <10>;
				vsync-len = <3>;
			};
		};
	};
};

&reg_usb_h1_vbus {
	gpio = <&gpio4 15 0>;
	enable-active-high;
};

&reg_usb_otg_vbus {
	gpio = <&gpio3 22 0>;
	enable-active-high;
};

&usdhc2 {	/* uSDHC2, MMC/SD card */
	wp-gpios = <>;
};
